[part 3 of 3: packages /AUTOSAR to /Volkswagen/EcuConfiguration]
AUTOSAR XML (schema 3.1.1)
package /AUTOSAR  (continued)
  module definition IoHwAbstraction [0..1]  # Configuration of IO HW Abstraction.
    container IoHwAbEcuSignalGroup [0..*]  # This container contains the configuration (parameters) of all ECU signals groups implemented in the IO Hardware Abstraction Module
      container IoHwAbDiscSigGrpInput [0..*]  # This container contains the description of a discrete ECU signal group. The container IoHwAb_Discrete_SignalGroup contains several IoHwAb_Class_Discrete_Input sub-containers
        reference IoHwAbDiscSigGrpInMember [1..*]: destination=IoHwAbDiscreteInput  # Each member of the signal group is referenced by an instance of tthis element. In the IO HW Abstraction SWS, individual signals are aggregated by the signal group instead of referenced, but by using references it is still possible to have the same signal being par of several signal groups, as intended in the SWS.
      container IoHwAbDiscSigGrpOutput [0..*]  # This container contains the description of a discrete ECU signal group. The container IoHwAb_Discrete_SignalGroup contains several IoHwAb_Class_Discrete_Output sub-containers.
        reference IoHwAbDiscSigGrpOutMember [1..*]: destination=IoHwAbDiscreteOutput  # Each member of the signal group is referenced by an instance of tthis element. In the IO HW Abstraction SWS, individual signals are aggregated by the signal group instead of referenced, but by using references it is still possible to have the same signal being par of several signal groups, as intended in the SWS.
    container IoHwAbEcuSignals [0..*]  # This container contains the configuration (parameters) of all ECU signals implemented in the IO Hardware Abstraction Module. Remarks: - The IO Hardware Abstraction module is an ECU firmware module. That means that the implementation shall fit only to the ECU hardware. The implementer has to develop only the functionality needed (eg: if there is no pulse width ECU signal configurated, the pulse width abstraction will not be available. - At least one ECU signal shall be configurated to have the module.
      container IoHwAbAnalogInput [0..*]  # This container contains the description of an analog ECU signal used as input. The operation available through the Port is a OP_GET.
        boolean IoHwAbAnaInputFilter  # This parameter specifies if the ECU analog signal is filtered
        boolean IoHwAbAnaInputReport  # This parameter specifies if the report features is activated
        integer IoHwAbAnaInputSamplingRate  # This parameter specifies the sampling rate for an analog input
        container IoHwAbAnalog  # This container contains common description of a all ECU signals from class analog.
          integer IoHwAbAnalogBswRange: 0..  # This parameter gives the BSW Range used for an analog signal, according to the datatype
          integer IoHwAbAnalogMaxAge  # This parameter gives the maximum age of an ECU analog signal
          string IoHwAbAnalogBswResolution  # This parameter gives the resolution used for an analog signal
          string IoHwAbAnalogDataType  # This parameter gives the DataType used for an analog signal
          string IoHwAbAnalogUnit  # This parameter gives the unit used for an analog signal
      container IoHwAbAnalogOutput [0..*]  # This container contains the description of an analog ECU signal used as output. The operation available through the Port is a OP_SET.
        boolean IoHwAbAnaOutputFailureMoni  # This parameter specifies if the ECU analog Output is monitored, to detect failure
        boolean IoHwAbAnaOutputPulseTest  # This parameter specifies if an test pulse is used to detect failure on the ECU analog Output
        container IoHwAbAnalog  # This container contains common description of a all ECU signals from class analog.
          integer IoHwAbAnalogBswRange: 0..  # This parameter gives the BSW Range used for an analog signal, according to the datatype
          integer IoHwAbAnalogMaxAge  # This parameter gives the maximum age of an ECU analog signal
          string IoHwAbAnalogBswResolution  # This parameter gives the resolution used for an analog signal
          string IoHwAbAnalogDataType  # This parameter gives the DataType used for an analog signal
          string IoHwAbAnalogUnit  # This parameter gives the unit used for an analog signal
      container IoHwAbDiscreteDiagnosis [0..*]  # This container contains the description of a discrete ECU signal used as diagnosis.
        container IoHwAbDiscrete  # This container contains common description of a all ECU signals from class discrete
          boolean IoHwAbDiscreteBswRange  # This parameter gives all possible values of an ECU discrete signal
          boolean IoHwAbDiscreteDatatype  # This parameter gives the DataType used for a discrete signal
          integer IoHwAbDiscreteMaxAge  # This parameter gives the maximum age of an ECU discrete signal
      container IoHwAbDiscreteInput [0..*]  # This container contains the description of a discrete ECU signal used as input. The operation available through the Port is an OP_GET.
        boolean IoHwAbDiscInputReport  # This parameter specifies if the report features is activated FALSE represents no report if a significant change occurs TRUE represents repot if a significant change occurs
        boolean IoHwAbDiscInputWakeup  # This parameter specifies if the ECU pin is a wakeup input TRUE represents a wakeup Input. During sleep mode, a change is reported to the module. In case of a valid reason, the ECU state manager will be restarted to validate the wakeup. FALSE represents a simple discrete Input.
        integer IoHwAbDiscInputDebounce  # This parameter specifies if the ECU discrete signal is filtered / debounced 0 represents Debouncing deactivated N represents Debouncing activated, N values sampled before value is available
        container IoHwAbDiscrete  # This container contains common description of a all ECU signals from class discrete
          boolean IoHwAbDiscreteBswRange  # This parameter gives all possible values of an ECU discrete signal
          boolean IoHwAbDiscreteDatatype  # This parameter gives the DataType used for a discrete signal
          integer IoHwAbDiscreteMaxAge  # This parameter gives the maximum age of an ECU discrete signal
      container IoHwAbDiscreteOutput [0..*]  # This container contains the description of a discrete ECU signal used as Output. The operation available through the Port is a OP_SET.
        boolean IoHwAbDiscOutputFailureMoni  # This parameter specifies if the ECU discrete Output is monitored, to detect failure TRUE represents that the ECU Signal is a monitored Output. Failures on this Output are detected and managed by the module FALSE represents that the ECU Signal is a simple discrete Output.
        boolean IoHwAbDiscOutputPulseTest  # This parameter specifies if an test pulse is used to detect failure on the ECU discrete Output TRUE represents that a Test Pulse is used for failure monitoring FALSE represents that no Test Pulse is used for failure monitoring
        container IoHwAbDiscrete  # This container contains common description of a all ECU signals from class discrete
          boolean IoHwAbDiscreteBswRange  # This parameter gives all possible values of an ECU discrete signal
          boolean IoHwAbDiscreteDatatype  # This parameter gives the DataType used for a discrete signal
          integer IoHwAbDiscreteMaxAge  # This parameter gives the maximum age of an ECU discrete signal
      container IoHwAbPwDutyCycleInput [0..*]  # This container contains specific description for an input ECU signal from class pulse width, handling especially the characteristic DutyCycle The operation available through the Port is a OP_GET
        boolean IoHwAbPwdcInputWakeup  # This parameter specifies if the ECU pin is a wakeup input
        container IoHwAbPwDutyCycle  # This container contains common description of a all ECU signals from class pulse width, handling especially the characteristic duty cycle
          integer IoHwAbPwdcBswRange: 0..100  # This parameter gives the BSW Range for a pulse width signal
          string IoHwAbPwdcUnit  # This parameter gives the unit for an ECU signal, handling especially the characteristic period
          container IoHwAbPulseWidth  # This container contains common description of a all ECU signals from class pulse width
            integer IoHwAbPwBswResolution  # This parameter gives the resolution used for a pulse width ECU signal
            integer IoHwAbPwMaxAge  # This parameter gives the maximum age for a pulse width ECU signal
            string IoHwAbPwDatatype  # This parameter gives the DataType used for a pulse width signal
      container IoHwAbPwDutyCycleOutput [0..*]  # This container contains specific description for an output ECU signal from class pulse width, handling especially the characteristic DutyCycle. The operation available through the Port is a OP_SET.
        boolean IoHwAbPwdcOutputFailureMoni  # This parameter specifies if the ECU Output is monitored, to detect failure
        boolean IoHwAbPwdcOutputPulseTest  # This parameter specifies if an test pulse is used to detect failure on the ECU Output
        container IoHwAbPwDutyCycle  # This container contains common description of a all ECU signals from class pulse width, handling especially the characteristic duty cycle
          integer IoHwAbPwdcBswRange: 0..100  # This parameter gives the BSW Range for a pulse width signal
          string IoHwAbPwdcUnit  # This parameter gives the unit for an ECU signal, handling especially the characteristic period
          container IoHwAbPulseWidth  # This container contains common description of a all ECU signals from class pulse width
            integer IoHwAbPwBswResolution  # This parameter gives the resolution used for a pulse width ECU signal
            integer IoHwAbPwMaxAge  # This parameter gives the maximum age for a pulse width ECU signal
            string IoHwAbPwDatatype  # This parameter gives the DataType used for a pulse width signal
      container IoHwAbPwPeriodInput [0..*]  # This container contains specific description for an input ECU signal from class pulse width, handling especially the characteristic period
        boolean IoHwAbPwpInputWakeup  # This parameter specifies if the ECU pin is a wakeup input
        container IoHwAbPwPeriod  # This container contains common description of a all ECU signals from class pulse width, handling especially the characteristic period
          integer IoHwAbPwpBswRange: -100..100  # This parameter gives the BSW Range for a pulse width signal (in percent)
          string IoHwAbPwpUnit  # This parameter gives the unit for an ECU signal, handling especially the characteristic period
          container IoHwAbPulseWidth  # This container contains common description of a all ECU signals from class pulse width
            integer IoHwAbPwBswResolution  # This parameter gives the resolution used for a pulse width ECU signal
            integer IoHwAbPwMaxAge  # This parameter gives the maximum age for a pulse width ECU signal
            string IoHwAbPwDatatype  # This parameter gives the DataType used for a pulse width signal
      container IoHwAbPwPeriodOutput [0..*]  # This container contains specific description for an output ECU signal from class pulse width, handling especially the characteristic period The operation available through the Port is a OP_SET.
        boolean IoHwAbPwpOutputFailureMoni  # This parameter specifies if the ECU Output is monitored, to detect failure
        boolean IoHwAbPwpOutputPulseTest  # This parameter specifies if an test pulse is used to detect failure on the ECU Output
        container IoHwAbPwPeriod  # This container contains common description of a all ECU signals from class pulse width, handling especially the characteristic period
          integer IoHwAbPwpBswRange: -100..100  # This parameter gives the BSW Range for a pulse width signal (in percent)
          string IoHwAbPwpUnit  # This parameter gives the unit for an ECU signal, handling especially the characteristic period
          container IoHwAbPulseWidth  # This container contains common description of a all ECU signals from class pulse width
            integer IoHwAbPwBswResolution  # This parameter gives the resolution used for a pulse width ECU signal
            integer IoHwAbPwMaxAge  # This parameter gives the maximum age for a pulse width ECU signal
            string IoHwAbPwDatatype  # This parameter gives the DataType used for a pulse width signal
    container IoHwAbGeneral  # This container contains common description for the IO Hardware Abstraction module
      boolean IoHwAbDevErrorDetect  # Switches the Development Error Detection and Notification ON or OFF
      boolean IoHwAbVersionInfoApi  # Pre-processor switch to enable / disable the API to read out the modules version information.
  module definition Lin [0..*]: variants pre-compile/post-build  # Configuration of the Lin (LIN driver) module.
    container LinGeneral
      boolean LinDevErrorDetect: set at pre-compile  # Switches the Development Error Detection and Notification ON or OFF.
      boolean LinVersionInfoApi: set at pre-compile  # Switches the Lin_GetVersionInfo function ON or OFF.
      integer LinIndex: set at pre-compile  # Specifies the InstanceId of this module instance. If only one instance is present it shall have the Id 0.
      integer LinTimeoutDuration: set at pre-compile  # Specifies the maximum number of loops for blocking function until a timeout is raised in short term wait loops
    container LinGlobalConfig: multiple-configuration-container=true  # This container contains the global configuration parameter of the Lin driver. This container is a MultipleConfigurationContainer, i.e. this container and its sub-containers exit once per configuration set.
      container LinChannel [1..*]  # This container contains the configuration (parameters) of the LIN Controller(s).
        boolean LinChannelWakeUpSupport: set at pre-compile  # Specifies if the LIN hardware channel supports wake up functionality
        integer LinChannelBaudRate: 1000..20000, set at pre-compile in variant pre-compile / post-build in variant post-build  # Specifies the baud rate of the LIN channel
        integer LinChannelId: set at pre-compile, symbolic-name-value=true  # Identifies the LIN channel. Replaces LIN_CHANNEL_INDEX_NAME from the LIN SWS.
        reference LinClockRef: set at pre-compile in variant pre-compile / post-build in variant post-build, destination=McuClockReferencePoint  # Reference to the LIN clock source configuration, which is set in the MCU driver configuration.
        symbolic name reference LinChannelEcuMWakeUpSource [0..1]: destination=EcuMWakeupSource  # This parameter contains a reference to the Wakeup Source for this controller as defined in the ECU State Manager. Implementation Type: reference to EcuM_WakeupSourceType
  module definition LinIf [0..1]: variants pre-compile/link-time/post-build  # Configuration of the LinIf (LIN Interface) module.
    container LinIfGeneral
      boolean LinIfDevErrorDetect: set at pre-compile  # Switches the Development Error Detection and Notification ON or OFF.
      boolean LinIfMultipleDriversSupported: set at pre-compile  # States if multiple drivers are included in the LIN Interface or not. The reason for this parameter is to reduce the size of LIN Interface if multiple drivers are not used.
      boolean LinIfNcOptionalRequestSupported: set at pre-compile  # States if the node configuration commands Assign NAD and Conditional Change NAD are supported.
      boolean LinIfTpSupported: set at pre-compile  # States if the TP is included in the LIN Interface or not. The reason for this parameter is to reduce the size of LIN Interface if the TP is not used.
      boolean LinIfVersionInfoApi: set at pre-compile  # Switches the LinIf_GetVersionInfo function ON or OFF.
    container LinIfGlobalConfig: multiple-configuration-container=true  # This container contains the global configuration parameter of the LinIf. It is a MultipleConfigurationContainer, i.e. this container and its sub-containers exit once per configuration set.
      float LinIfTimeBase: set at link in variant link-time / pre-compile in variant pre-compile / post-build in variant post-build  # The time-base for this channel in s (normally 0.002, 0.005 or 0.010s)
      container LinIfChannel [1..*]
        integer LinIfChannelId: set at link in variant link-time+post-build / pre-compile in variant pre-compile, symbolic-name-value=true  # Internal ID for the channel on LIN Interface level. This parameter shall map the NetworkHandleType to the physical LIN channel. Implementation Type: NetworkHandleType
        integer LinIfScheduleRequestQueueLength: 1..255, set at link in variant link-time / pre-compile in variant pre-compile / post-build in variant post-build  # Number of schedule requests the schedule table manager can handle for this channel.
        symbolic name reference LinIfChannelRef: destination=LinChannel  # Reference to the used channel in Lin. Replaces LINIF_CHANNEL_INDEX
        container LinIfFrame [0..*]  # Generic container for all types of LIN frames.
          enumeration LinIfChecksumType: {CLASSIC, ENHANCED}, set at link in variant link-time / pre-compile in variant pre-compile / post-build in variant post-build  # Type of checksum that the frame is using.
          enumeration LinIfFrameType: {ASSIGN, ASSIGN_NAD, CONDITIONAL, EVENT_TRIGGERED, FREE, MRF, SPORADIC, SRF, UNASSIGN, UNCONDITIONAL}, set at link in variant link-time / pre-compile in variant pre-compile / post-build in variant post-build  # Type of frame that is described (e.g. sporadic frame). Note that types 7-11 are the fixed MRF types. The sporadic slot is not found among the frame types. A sporadic slot is a set of sporadic frames.
          integer LinIfFramePriority: 0..255, set at link in variant link-time / pre-compile in variant pre-compile / post-build in variant post-build  # Priority of an unconditional frame if used as a sporadic frame or in case of collision resolving of event triggered frames
          integer LinIfLength: 1..8, set at link in variant link-time / pre-compile in variant pre-compile / post-build in variant post-build  # Length of the LIN SDU in bytes.
          integer LinIfPid: 0.., set at link in variant link-time / pre-compile in variant pre-compile / post-build in variant post-build  # Protected ID of the LIN frame. There is no reason to calculate the Parity in run-time.
          integer LinIfTxTargetPduId: set at link in variant link-time / pre-compile in variant pre-compile / post-build in variant post-build  # Identifier of the frame for the upper layer
          string LinIfFrameName [0..1]: set at link in variant link-time / pre-compile in variant pre-compile / post-build in variant post-build  # Optional frame name used to cross-reference with a LDF
          choice container LinIfPduDirection  # Direction of the frame
            container LinIfInternalPdu [0..1]  # Represents a Diagnostic or Configuration frame : no Message ID (no PduId).
            container LinIfRxPdu [0..1]  # represents a received PDU/frame
              integer LinIfRxPduId: set at link in variant link-time / pre-compile in variant pre-compile / post-build in variant post-build, symbolic-name-value=true  # dentifier of the frame for the LIN Interface
              reference LinIfRxPduRef: destination=Pdu  # Reference to the PDU that is received in this frame.
            container LinIfSlaveToSlavePdu [0..1]  # represents a slave-to-slave PDU/frame. Master does only send the header but doesn't receive the response. Added for completeness
            container LinIfTxPdu [0..1]  # represents a transmitted PDU/frame
              integer LinIfTxPduId: set at link in variant link-time / pre-compile in variant pre-compile / post-build in variant post-build, symbolic-name-value=true  # Identifier of the frame for the upper layer. This id is only relevant for sporadic frames.
              reference LinIfTxPduRef: destination=Pdu  # Reference to the PDU that is transmitted in this frame.
          container LinIfFixedFrameSdu [0..1]  # In case this is a fixed frame this is the SDU (response). This value should represent an eight byte array. The Byte order shall be MSB first.
            integer LinIfFixedFrameSduBytePos: 1..8, set at link in variant link-time / pre-compile in variant pre-compile / post-build in variant post-build  # Index of the Byte in the SDU (response) 8 byte array.
            integer LinIfFixedFrameSduByteVal: 0..255, set at link in variant link-time / pre-compile in variant pre-compile / post-build in variant post-build  # Byte value in the SDU (response) 8-byte array.
          container LinIfSubstitutionFrames [0..*]  # List of unconditional Frames that can be sent in an event-triggered Frame or a sporadic Frame slot.
            reference LinIfSubstitutionFrameRef: destination=LinIfFrame  # Reference to an unconditional Frame that can be sent in an event-triggered Frame or a sporadic Frame slot.
        container LinIfMaster  # Each Master can only be connected to one physical channel. This could be compared to the Node parameter in a LDF file.
          integer LinIfJitter: set at pre-compile  # Specifies the difference and the maximum and the minimum delay (ms)
        container LinIfScheduleTable [1..*]  # Describes a schedule table. Each LinIfChannel may have several schedule tables. Each schedule table can only be connected to one channel.
          enumeration LinIfResumePosition: {CONTINUE_AT_IT_POINT, START_FROM_BEGINNING}, set at link in variant link-time / pre-compile in variant pre-compile / post-build in variant post-build  # Defines, where a schedule table shall be proceeded in case if it has been interrupted by a run-once table or MRF/SRF.
          enumeration LinIfRunMode: {RUN_CONTINUOUS, RUN_ONCE}, set at link in variant link-time / pre-compile in variant pre-compile / post-build in variant post-build  # The schedule table can be executed in two different modes.
          integer LinIfSchedulePriority: 0..255, set at link in variant link-time / pre-compile in variant pre-compile / post-build in variant post-build  # Priority of the schedule table. The priority is used in the schedule table manager. The RUN_ONCE run mode schedules shall not have equal priority. 0 Reserved for NULL__SCHEDULE 1..254 Only for RUN_ONCE 255 Only RUN_CONTINUOUS
          integer LinIfScheduleTableIndex: set at link in variant link-time / pre-compile in variant pre-compile / post-build in variant post-build, symbolic-name-value=true  # This is the unique index used by upper layers to identify a schedule. Note that the NULL_SCHEDULE for each channel has index 0.
          string LinIfScheduleTableName [0..1]: set at link in variant link-time / pre-compile in variant pre-compile / post-build in variant post-build  # Optional schedule name used to cross-reference with a LDF. This parameter shall always be accompanied by LIN_IF_SCHEDULE_INDEX.
          container LinIfEntry [0..*]  # Describes an entry in the schedule table (also known as Frame Slot).
            float LinIfDelay: set at link in variant link-time / pre-compile in variant pre-compile / post-build in variant post-build  # Delay to next frame in schedule table in [s]
            integer LinIfEntryIndex  # Position of the Frame Entry in the Schedule Table.
            reference LinIfCollisionResolvingRef [0..1]: destination=LinIfScheduleTable  # Reference to the schedule table, which resolves the collision.
            reference LinIfFrameRef [1..*]: set at link in variant link-time / pre-compile in variant pre-compile / post-build in variant post-build, destination=LinIfFrame  # Reference to the frames that belong to this schedule table entry.
        container LinIfSlave [0..*]  # The Node attributes of the Slaves are provided with these parameter.
          integer LinIfConfiguredNad: set at pre-compile  # Definition of the initial node address
          integer LinIfFunctionId: set at pre-compile  # LIN function ID
          integer LinIfResponseErrorBitPos: set at pre-compile  # Specifies the frame and the position in the frame
          integer LinIfSupplierId: set at pre-compile  # LIN Supplier ID
          integer LinIfVariant: set at pre-compile  # Specifies the Variant ID
          string LinIfProtocolVersion: set at pre-compile  # Defines the LIN Protocol version which is used by the slave.
          reference LinIfResponseErrorEventRef: destination=DemEventParameter  # Reference to DEM Event
          reference LinIfResponseErrorFrameRef: destination=LinIfFrame  # Reference to the frame which contains the response error bit.
          container LinIfNodeComposition  # Generic container that describes the node composition
            string LinIfNodeName: set at pre-compile
        container LinIfWakeUpSource [0..1]  # This container contains the configuration (parameters) needed to configure a wakeup capable channel
          symbolic name reference LinIfChannelWakeupInfo: destination=EcuMWakeupSource  # If the wakeup-capability is true the wakeup source referenced is transmitted to the ECU State Manager (EcuM) . Implementation Type: reference to EcuM_WakeupSourceType
  module definition LinSM [0..1]: variants pre-compile/link-time  # Configuration of the Lin State Manager module.
    container LinSMChannel [1..*]: multiple-configuration-container=true  # Describes each LIN channel the LinSM is connected to.
      boolean LinSMSleepSupport: set at link in variant link-time / pre-compile in variant pre-compile  # Some LIN clusters does not need sleep, they will just shut off. This parameter will affect the behavior to achieve the no communication state. True - The LinSM will request the LinIf to send the goto sleep command before going to no communication state LINSM_NOCOM. False - The LinSM will directly go to no communication state LINSM_NOCOM.
      float LinSMConfirmationTimeout: set at link in variant link-time / pre-compile in variant pre-compile  # Timeout in seconds for the goto sleep and wakeup calls to LinIf. The timeout must be longer than a goto-sleep command on the bus (i.e. it is bit rate dependent).
      symbolic name reference LinSMChannelIndex: destination=LinIfChannel  # Index of the controller. To be able to interface to the correct hw.
      container LinSMSchedule [1..*]  # The schedule references to a schedule that is located in the LinIf configuration. Moreover, the PDU groups are located in the COM configuration. Note that there are two references to PDU groups. The simple reason is that a PDU group is only allowed to contain one direction (TX or RX).
        symbolic name reference LinSMRxPduGroupRef: destination=ComIPduGroup  # This is a reference to the PDU group containing the received frames in the Com configuration
        symbolic name reference LinSMScheduleIndexRef: destination=LinIfScheduleTable  # Reference to a schedule table in the LinIf configuration
        symbolic name reference LinSMTxPduGroupRef: destination=ComIPduGroup  # This is a reference to the PDU group containing the transmitted frames in the Com configuration
    container LinSMGeneral  # The general parameters fo this module.
      boolean LinSMDevErrorDetect: set at pre-compile  # Switches the Development Error Detection and Notification ON or OFF.
      boolean LinSMVersionInfoApi: set at pre-compile  # Switches the LinSM_GetVersionInfo function ON or OFF.
  module definition LinTp [0..1]: variants pre-compile/link-time/post-build  # Singleton descriptor for the LIN Transport Protocol.
    container LinTpGeneral  # Container that holds all LIN transport protocol general parameters.
      boolean LinTpVersionInfoApi: set at pre-compile  # Switches the LinTp_GetVersionInfo function ON or OFF.
    container LinTpGlobalConfig: multiple-configuration-container=true  # This container contains the global configuration parameter of the LinTp. It is a MultipleConfigurationContainer, i.e. this container and its sub-containers exit once per configuration set.
      integer LinTpNumberOfRxNSdu: set at link in variant link-time / pre-compile in variant pre-compile / post-build in variant post-build  # Number of transport protocol messages that can be received for all channels this node is connected to. Can't that be calculated from the NSdus?
      integer LinTpNumberOfTxNSdu: set at link in variant link-time / pre-compile in variant pre-compile / post-build in variant post-build  # Number of transport protocol messages that can be transmitted for all channels this node is connected to.
      container LinTpRxNSdu [0..*]  # For each received N-SDU on any channel the node is connected to.
        integer LinTpDl: set at link in variant link-time / pre-compile in variant pre-compile / post-build in variant post-build  # Data Length Code of this RxNsdu. In case of variable length message, this value indicates the minimum data length. Range of minimum length is 1 to 4095. Note that this is not relevant for Tx. The reason for this is to have identical structures for Tx and Rx.
        integer LinTpRxNSduId: set at link in variant link-time / pre-compile in variant pre-compile / post-build in variant post-build, symbolic-name-value=true  # The identifier of the Transport Protocol message. This ID will be the one that is communicated with upper layers.
        integer LinTpRxNSduNad: set at link in variant link-time / pre-compile in variant pre-compile / post-build in variant post-build  # A N-SDU transported on LIN is identified using the NAD for the specific slave.
        reference LinTpRxNSduPduRef: destination=Pdu  # Reference to the global PDU
        symbolic name reference LinTpRxNSduChannelRef: destination=LinIfChannel  # Index of the channel this N-SDU belongs to.
      container LinTpTxNSdu [0..*]  # For each transmitted N-SDU on any channel the node is connected to.
        integer LinTpTxNSduId: set at link in variant link-time / pre-compile in variant pre-compile / post-build in variant post-build, symbolic-name-value=true  # The identifier of the Transport Protocol message. This ID will be the one that is communicated with upper layers.
        integer LinTpTxNSduNad: set at link in variant link-time / pre-compile in variant pre-compile / post-build in variant post-build  # A N-SDU transported on LIN is identified using the NAD for the specific slave.
        reference LinTpTxNSduPduRef: destination=Pdu  # Reference to the global PDU
        symbolic name reference LinTpTxNSduChannelRef: destination=LinIfChannel  # Index of the channel this N-SDU belongs to.
  module definition Mcu [0..1]: variants pre-compile/post-build  # Configuration of the Mcu (Microcontroler Unit) module.
    container McuGeneralConfiguration  # This container contains the configuration (parameters) of the MCU driver.
      boolean McuDevErrorDetect: set at pre-compile  # Pre-processor switch for enabling the development error detection and reporting.
      boolean McuPerformResetApi: set at pre-compile  # Pre-processor switch to enable / disable the use of the function Mcu_PerformReset()
      boolean McuVersionInfoApi: set at pre-compile  # Pre-processor switch to enable / disable the API to read out the modules version information.
    container McuModuleConfiguration: multiple-configuration-container=true  # This container contains the configuration (parameters) of the MCU driver
      derived integer McuNumberOfMcuModes: calculation-formula=number of configured mcumodesettingconf, calculation-language=INFORMAL  # This parameter shall represent the number of Modes available for the MCU. calculationFormula = Number of configured McuModeSettingConf
      derived integer McuRamSectors: set at pre-compile in variant pre-compile / post-build in variant post-build, calculation-formula=number of configured mcuramsectorsettingconf, calculation-language=INFORMAL  # This parameter shall represent the number of RAM sectors available for the MCU. calculationFormula = Number of configured McuRamSectorSettingConf
      enumeration McuClockSrcFailureNotification: {DISABLED, ENABLED}, set at pre-compile in variant pre-compile / post-build in variant post-build  # Enables/Disables clock failure notification. In case this feature is not supported by HW the setting should be disabled.
      integer McuResetSetting [0..1]: set at pre-compile  # This parameter relates to the MCU specific reset configuration. This applies to the function Mcu_PerformReset, which performs a microcontroller reset using the hardware feature of the microcontroller.
      container McuClockSettingConfig  # This container contains the configuration (parameters) for the Clock settings of the MCU. Please see MCU031 for more information on the MCU clock settings.
        container McuClockReferencePoint [1..*]  # This container defines a reference point in the Mcu Clock tree. It defines the frequency which then can be used by other modules as an input value. Lower multiplictiy is 1, as even in the simpliest case (only one frequency is used), there is one frequency to be defined.
          float McuClockReferencePointFrequency: set at pre-compile in variant pre-compile / post-build in variant post-build  # This is the frequency for the specific instance of the McuClockReferencePoint container. It shall be givn in Hz.
      container McuModeSettingConf [1..*]  # This container contains the configuration (parameters) for the Mode setting of the MCU. Please see MCU035 for more information on the MCU mode settings.
        integer McuMode: set at pre-compile in variant pre-compile / post-build in variant post-build, symbolic-name-value=true  # The parameter represents the MCU Mode settings.
      container McuRamSectorSettingConf [0..*]  # This container contains the configuration (parameters) for the RAM Sector setting. Please see MCU030 for more information on RAM sec-tor settings.
        integer McuRamDefaultValue: set at pre-compile in variant pre-compile / post-build in variant post-build  # This parameter shall represent the Data pre-setting to be initialized
        integer McuRamSectionBaseAddress: set at pre-compile in variant pre-compile / post-build in variant post-build  # This parameter shall represent the MCU RAM section base address
        integer McuRamSectionSize: set at pre-compile in variant pre-compile / post-build in variant post-build  # This parameter shall represent the MCU RAM Section size
  module definition MemIf [0..1]: variants pre-compile  # Configuration of the MemIf (Memory Abstraction Interface) module.
    container MemIfGeneral  # Configuration of the memory abstraction interface (Memif) module.
      boolean MemIfDevErrorDetect: set at pre-compile  # Pre-processor switch to enable and disable development error detection. true: Development error detection enabled. false: Development error detection disabled.
      boolean MemIfVersionInfoApi: set at pre-compile  # Pre-processor switch to enable / disable the API to read out the modules version information. true: Version info API enabled. false: Version info API disabled.
      derived integer MemIfNumberOfDevices: 1..255, set at pre-compile, calculation-language=INFORMAL  # Concrete number of underlying memory abstraction modules.
  module definition Nm [0..1]: variants pre-compile  # The Generic Network Management Interface module
    container NmGlobalConfig  # This container contains all global configuration parameters of the Nm Interface.
      boolean NmBusSynchronizationEnabled: set at pre-compile  # Pre-processor switch for enabling bus synchronization support. This feature is required for gateway nodes only.
      boolean NmComControlEnabled: set at pre-compile  # Pre-processor switch for enabling the Communication Control support.
      boolean NmCoordinatorSupportEnabled: set at pre-compile, default-value=false  # Switch to inform if NM coordinator needs to be supported.
      boolean NmDevErrorDetect: set at pre-compile, default-value=false  # Pre-processor switch for enabling development error detection and notification.
      boolean NmMultipleChannelsEnabled: set at pre-compile, default-value=false  # Pre-processor switch for enabling channel multiplicity support.
      boolean NmNodeDetectionEnabled: set at pre-compile  # Pre-processor switch for enabling the Request Repeat Message Request support.
      boolean NmNodeIdEnabled: set at pre-compile  # Pre-processor switch for enabling the source node identifier.
      boolean NmOsekSupportEnabled: set at pre-compile, default-value=false  # Switch to inform if NM coordinator needs to support direct OSEK NM.
      boolean NmPassiveModeEnabled: set at pre-compile  # Pre-processor switch for enabling support of the Passive Mode.
      boolean NmPduRxIndicationEnabled: set at pre-compile  # Pre-processor switch for enabling the PDU Rx Indication.
      boolean NmRemoteSleepIndEnabled: set at pre-compile  # Pre-processor switch for enabling remote sleep indication support. This feature is required for gateway nodes only.
      boolean NmStateChangeIndEnabled: set at pre-compile  # Pre-processor switch for enabling the CAN Network Management state change notification.
      boolean NmUserDataEnabled: set at pre-compile  # Pre-processor switch for enabling user data support.
      boolean NmVersionInfoApi: set at pre-compile  # Pre-processor switch for enabling version info API support.
      float NmCycletimeMainFunction: set at pre-compile  # The period between successive calls to the Main Function of the NM Interface in seconds.
      integer NmAutosarGatewayRounds: set at pre-compile  # Number of rounds the coordinator shall keep a bus which runs AUTOSAR NM awake after all nodes including itself are ready to sleep.
      integer NmNumberOfChannels: 1..255, set at pre-compile  # Number of NM channels allowed within one ECU.
      integer NmOsekGatewayRounds: set at pre-compile  # Number of rounds the coordinator shall keep a bus which runs OSEK NM awake after all nodes including itself are ready to sleep.
      container NmChannelConfig [1..*]  # This container contains the configuration (parameters) of the bus channel(s). The channel parameter shall be harmonized within the whole communication stack.
        enumeration NmBusType: {NM_BUS_TYPE_CAN, NM_BUS_TYPE_FR, NM_BUS_TYPE_LIN}, set at pre-compile  # Identifies the bus type of the channel. LIN is not yet supported.
        integer NmChannelId: 0..255, set at pre-compile, symbolic-name-value=true  # Channel identification number of the corresponding channel.
        symbolic name reference NmComMChannelRef: destination=ComMChannel  # Reference to the corresponding ComM Channel.
  module definition NvM [0..1]: variants pre-compile  # Configuration of the NvM (NvRam Manager) module.
    container NvmBlockDescriptor [1..65536]  # Container for a management structure to configure the composition of a given NVRAM Block Management Type. Its multiplicity describes thenumber of configured NVRAM blocks, one block is required to be configured. The NVRAM block descriptors are condensed in the NVRAM block descriptor table.
      boolean NvmBlockUseCrc: set at pre-compile  # Defines CRC usage for the NVRAM block, i.e. memory space for CRC is reserved in RAM and NV memory. true: CRC will be used for this NVRAM block. false: CRC will not be used for this NVRAM block.
      boolean NvmBlockWriteProt: set at pre-compile  # Defines an initial write protection of the NV block true: Initial block write protection is enabled. false: Initial block write protection is disabled.
      boolean NvmCalcRamBlockCrc: set at pre-compile  # Defines CRC (re)calculation for the permanent RAM block true: CRC will be (re)calculated for this permanent RAM block. false: CRC will not be (re)calculated for this permanent RAM block.
      boolean NvmResistantToChangedSw: set at pre-compile  # Defines whether a NVRAM block shall be treated resistant to configuration changes or not. If there is no default data available at configuration time then the application shall be responsible for providing the default initialization data. In this case the application has to use NvM_GetErrorStatus()to be able to distinguish between first initialization and corrupted data. true: NVRAM block is resistant to changed software. false: NVRAM block is not resistant to changed software.
      boolean NvmSelectBlockForReadall: set at pre-compile  # NVM117: Defines whether a NVRAM block shall be processed during NvM_ReadAll or not. This configuration parameter has only influence on those NVRAM blocks which are configured to have a permanent RAM block. NVM245: Blocks of management type NVM_BLOCK_DATASET shall not be loaded automatically upon start-up. Thus the selection of blocks, which belong to block management type NVM_BLOCK_DATASET, shall not be possible for the service NvM_ReadAll. true: NVRAM block shall be processed by NvM_ReadAll false: NVRAM block shall not be processed by NvM_ReadAll
      boolean NvmWriteBlockOnce: set at pre-compile  # Defines write protection after first write. The NVRAM manager sets the write protection bit after the NV block was written the first time. This means that some of the NV blocks in the NVRAM should never be erased nor be replaced with the default ROM data after first initialization. [NVM276]. true: Defines write protection after first write is enabled. false: Defines write protection after first write is disabled.
      derived integer NvmNvBlockBaseNumber: set at pre-compile, calculation-language=INFORMAL  # Configuration parameter to perform the link between the NVM_NVRAM_BLOCK_IDENTIFIER used by the SW-Cs and the FEE_BLOCK_NUMBER expected by the memory abstraction modules. The parameter relates directly to the FEE_BLOCK_NUMBER or EA_BLOCK_NUMBER with all configured NVM_DATASET_SELECTION_BITS set to zero (ref. to chapter 7.1.2.1). Calculation Formula: "value = TargetBlockReference.[Ea/Fee]BlockConfiguration.[Ea/Fee]BlockNumber"
      derived integer NvmNvramDeviceId: set at pre-compile, calculation-language=INFORMAL  # Defines the NVRAM device ID where the NVRAM block is located. Calculation Formula: "value = TargetBlockReference.[Ea/Fee]BlockConfiguration.[Ea/Fee]DeviceIndex"
      enumeration NvmBlockCRCType: {NVM_CRC16, NVM_CRC32}, set at pre-compile  # Defines CRC data width for the NVRAM block. Default: NVM_CRC16, i.e. CRC16 will be used if NVM_BLOCK_USE_CRC==TRUE
      enumeration NvmBlockManagementType: {NVM_BLOCK_DATASET, NVM_BLOCK_NATIVE, NVM_BLOCK_REDUNDANT}, set at pre-compile  # Defines the block management type for the NVRAM block.[NVM137]
      function name NvmInitBlockCallback: set at pre-compile  # Entry address of a block specific callback routine which shall be called if no ROM data is available for initialization of the NVRAM block. If a NULL pointer is configured, no specific callback routine shall be called for initialization of the NVRAM block with default data.
      function name NvmSingleBlockCallback: set at pre-compile  # Entry address of the block specific callback routine which shall be invoked on termination of each asynchronous single block request [NVM113].
      integer NvmBlockJobPriority: 0..255, set at pre-compile  # Defines the job priority for a NVRAM block (0 = Immediate priority).
      integer NvmNvBlockLength: 1..65535, set at pre-compile  # Defines the NV block data length in bytes
      integer NvmNvBlockNum: 1..255, set at pre-compile  # Defines the number of multiple NV blocks in a contiguous area according to the given block management type. 1-255 For NVRAM blocks to be configured of block management type NVM_BLOCK_DATASET. The actual range is limited according to NVM148. 1 For NVRAM blocks to be configured of block management type NVM_BLOCK_NATIVE 2 For NVRAM blocks to be configured of block management type NVM_BLOCK_REDUNDANT
      integer NvmNvramBlockIdentifier: 0.., set at pre-compile, symbolic-name-value=true  # Identification of a NVRAM block via a unique block identifier. Implementation Type: NvM_BlockIdType. min = 0 max = 2^(16- NVM_DATASET_SELECTION_BITS)-1 Reserved NVRAM block IDs: 0 -> to derive multi block request results via NvM_GetErrorStatus 1 -> redundant NVRAM block which holds the configuration ID
      integer NvmRomBlockNum: set at pre-compile  # Defines the number of multiple ROM blocks in a contiguous area according to the given block management type. 0-255 For NVRAM blocks to be configured of block management type NVM_BLOCK_DATASET. The actual range is limited according to NVM148. 0-1 For NVRAM blocks to be configured of block management type NVM_BLOCK_NATIVE 0-1 For NVRAM blocks to be configured of block management type NVM_BLOCK_REDUNDANT
      string NvmRamBlockDataAddress: set at pre-compile  # Defines the start address of the RAM block data. If a NULL pointer is configured, no permanent RAM data block is available for the selected block management type.
      string NvmRomBlockDataAddress: set at pre-compile  # Defines the start address of the ROM block data. If a NULL pointer is configured, no ROM block is available for the selected block management type.
      choice container NvmTargetBlockReference
        container NvmEaRef [0..1]  # EEPROM Abstraction
          symbolic name reference NvmNameOfEaBlock: destination=EaBlockConfiguration  # reference to EaBlock
        container NvmFeeRef [0..1]  # Flash EEPROM Emulation
          symbolic name reference NvmNameOfFeeBlock: destination=FeeBlockConfiguration  # reference to FeeBlock
    container NvmCommon  # Container for common configuration options.
      boolean NvmDevErrorDetect: set at pre-compile  # Pre-processor switch to enable and disable development error detection. true: Development error detection enabled. false: Development error detection disabled.
      boolean NvmDrvModeSwitch: set at pre-compile  # Preprocessor switch to enable switching memory drivers to fast mode during performing NvM_ReadAll and NvM_WriteAll true: Fast mode enabled. false: Fast mode disabled.
      boolean NvmDynamicConfiguration: set at pre-compile  # Preprocessor switch to enable the dynamic configuration management handling by the NvM_ReadAll request. true: Dynamic configuration management handling enabled. false: Dynamic configuration management handling disabled.
      boolean NvmJobPrioritization: set at pre-compile  # Preprocessor switch to enable job prioritization handling true: Job prioritization handling enabled. false: Job prioritization handling disabled.
      boolean NvmPollingMode: set at pre-compile  # Preprocessor switch to enable/disable the polling mode in the NVRAM Manager and at the same time disable/enable the callback functions useable by lower layers true: Polling mode enabled, callback function usage disabled. false: Polling mode disabled, callback function usage enabled.
      boolean NvmSetRamBlockStatusApi: set at pre-compile  # Preprocessor switch to enable the API NvM_SetRamBlockStatus. true: API NvM_SetRamBlockStatus enabled. false: API NvM_SetRamBlockStatus disabled.
      boolean NvmVersionInfoApi: set at pre-compile  # Pre-processor switch to enable / disable the API to read out the modules version information [NVM285], [NVM286]. true: Version info API enabled. false: Version info API disabled.
      enumeration NvmApiConfigClass: {NVM_API_CONFIG_CLASS_1, NVM_API_CONFIG_CLASS_2, NVM_API_CONFIG_CLASS_3}, set at pre-compile  # Preprocessor switch to enable some API calls which are related to NVM API configuration classes.
      function name NvmMultiBlockCallback: set at pre-compile  # Entry address of the common callback routine which shall be invoked on termination of each asynchronous multi block request
      integer NvmCompiledConfigId: 0..65535, set at pre-compile  # Configuration ID regarding the NV memory layout. This configuration ID shall be published as e.g. a SW-C shall have the possibility to write it to NV memory.
      integer NvmCrcNumOfBytes: 1..65535, set at pre-compile  # If CRC is configured for at least one NVRAM block, this parameter defines the maximum number of bytes which shall be processed within one cycle of job processing.
      integer NvmDatasetSelectionBits: 0..8, set at pre-compile  # Defines the number of least significant bits which shall be used to address a certain dataset of a NVRAM block within the interface to the memory hardware abstraction. 0..8: Number of bits which are used for dataset or redundant block addressing. 0: No dataset or redundant NVRAM blocks are configured at all, no selection bits required. 1: In case of redundant NVRAM blocks are configured, but no dataset NVRAM blocks.
      integer NvmMaxNoOfWriteRetries: 0..7, set at pre-compile  # Defines the maximum number of write retries for a NVRAM block with [NVM061]. Regardless of configuration a consistency check (and maybe write retries) are always forced for each block which is processed by the request NvM_WriteAll and NvM_WriteBlock.
      integer NvmSizeImmediateJobQueue: 1..255, set at pre-compile  # Defines the number of queue entries for the immediate priority job queue. If NVM_JOB_PRIORITIZATION is switched OFF this parameter shall be out of scope.
      integer NvmSizeStandardJobQueue: 1..255, set at pre-compile  # Defines the number of queue entries for the standard job queue.
  module definition Os [0..1]: variants pre-compile  # Configuration of the Os (Operating System) module.
    container OsAlarm [0..*]  # An OsAlarm may be used to asynchronously inform or activate a specific task. It is possible to start alarms automatically at system start-up depending on the application mode.
      reference OsAlarmAccessingApplication [0..*]: set at pre-compile, destination=OsApplication  # Reference to applications which have an access to this object.
      reference OsAlarmCounterRef: set at pre-compile, destination=OsCounter  # Reference to the assigned counter for that alarm
      choice container OsAlarmAction  # This container defines which type of notification is used when the alarm expires.
        container OsAlarmActivateTask [0..1]  # This container specifies the parameters to activate a task.
          reference OsAlarmActivateTaskRef: set at pre-compile, destination=OsTask  # Reference to the task that will be activated by that alarm action
        container OsAlarmCallback [0..1]  # This container specifies the parameters to call a callback OS alarm action.
          function name OsAlarmCallbackName: set at pre-compile  # Name of the function that is called when this alarm callback is triggered.
        container OsAlarmIncrementCounter [0..1]  # This container specifies the parameters to increment a counter.
          reference OsAlarmIncrementCounterRef: set at pre-compile, destination=OsCounter  # Reference to the counter that will be incremented by that alarm action
        container OsAlarmSetEvent [0..1]  # This container specifies the parameters to set an event
          reference OsAlarmSetEventRef: set at pre-compile, destination=OsEvent  # Reference to the event that will be set by that alarm action
          reference OsAlarmSetEventTaskRef: set at pre-compile, destination=OsTask  # Reference to the task that will be activated by that event
      container OsAlarmAutostart [0..1]  # If present this container defines if an alarm is started automatically at system start-up depending on the application mode.
        enumeration OsAlarmAutostartType: {ABSOLUTE, RELATIVE}, set at pre-compile  # This specifies the type of autostart for the alarm..
        integer OsAlarmAlarmTime: set at pre-compile  # The relative or absolute tick value when the alarm expires for the first time. Note that for an alarm which is RELATIVE the value must be at bigger than 0.
        integer OsAlarmCycleTime: set at pre-compile  # Cycle time of a cyclic alarm in ticks. If the value is 0 than the alarm is not cyclic.
        reference OsAlarmAppModeRef [1..*]: set at pre-compile, destination=OsAppMode  # Reference to the application modes for which the AUTOSTART shall be performed
    container OsAppMode [1..*]  # OsAppMode is the object used to define OSEK OS properties for an OSEK OS application mode. No standard attributes are defined for AppMode. In a CPU, at least one AppMode object has to be defined. [source: OSEK OIL Spec. 2.5] An OsAppMode called OSDEFAULTAPPMODE must always be there for OSEK compatilbility.
      integer OsAppModeId: set at pre-compile, symbolic-name-value=true  # Internal ID of an AppMode. Necessary, so that an AppMode is addressable by other modules.
    container OsApplication [0..*]  # An AUTOSAR OS must be capable of supporting a collection of OS objects (tasks, interrupts, alarms, hooks etc.) that form a cohesive functional unit. This collection of objects is termed an OS-Application. All objects which belong to the same OS-Application have access to each other. Access means to allow to use these objects within API services. Access by other applications can be granted separately.
      boolean OsTrusted: set at pre-compile, default-value=false  # Parameter to specify if an OS-Application is trusted or not. true: OS-Application is trusted false: OS-Application is not trusted (default)
      reference OsAppAlarmRef [0..*]: set at pre-compile, destination=OsAlarm  # Specifies the OsAlarms that belong to the OsApplication.
      reference OsAppCounterRef [0..*]: set at pre-compile, destination=OsCounter  # References the OsCounters that belong to the OsApplication.
      reference OsAppIsrRef [0..*]: set at pre-compile, destination=OsIsr  # references which OsIsrs belong to the OsApplication
      reference OsAppResourceRef [0..*]: set at pre-compile, destination=OsResource  # References the OsResources that belong to the OsApplication.
      reference OsAppScheduleTableRef [0..*]: set at pre-compile, destination=OsScheduleTable  # References the OsScheduleTables that belong to the OsApplication.
      reference OsAppTaskRef [0..*]: set at pre-compile, destination=OsTask  # references which OsTasks belong to the OsApplication
      reference OsRestartTask [0..1]: set at pre-compile, destination=OsTask  # Optionally one task of an OS-Application may be defined as Restart Task. Multiplicity = 1: Restart Task is activated by the Operating System if the protection hook requests it. Multiplicity = 0: No task is automatically started after a protection error happened.
      container OsApplicationHooks  # Container to structure the OS-Application-specific hooks
        boolean OsAppErrorHook: set at pre-compile  # Select the OS-Application error hook. true: Hook is called false: Hook is not called
        boolean OsAppShutdownHook: set at pre-compile  # Select the OS-Application specific shutdown hook for the OS-Application. true: Hook is called false: Hook is not called
        boolean OsAppStartupHook: set at pre-compile  # Select the OS-Application specific startup hook for the OS-Application. true: Hook is called false: Hook is not called
      container OsApplicationTrustedFunction [0..*]  # Container to structure the configration parameters of trusted functions
        function name OsTrustedFunctionName: set at pre-compile  # Trusted function (as part of a trusted OS-Application) available to other OS-Applications. This also supersedes the OSEK OIL attribute TRUSTED in APPLICATION because the optionality of this parameter is describing that already.
    container OsCounter [0..*]  # Configuration information for the counters that belong to the OsApplication.
      enumeration OsCounterType: {HARDWARE, SOFTWARE}, set at pre-compile  # This parameter contains the natural type or unit of the counter.
      float OsSecondsPerTick [0..1]: set at pre-compile  # Time of one hardware tick in seconds.
      integer OsCounterMaxAllowedValue: set at pre-compile  # Maximum possible allowed value of the system counter in ticks.
      integer OsCounterMinCycle: set at pre-compile  # The MINCYCLE attribute specifies the minimum allowed number of counter ticks for a cyclic alarm linked to the counter.
      integer OsCounterTicksPerBase: set at pre-compile  # The TICKSPERBASE attribute specifies the number of ticks required to reach a counterspecific unit. The interpretation is implementation-specific.
      reference OsCounterAccessingApplication [0..*]: set at pre-compile, destination=OsApplication  # Reference to applications which have an access to this object.
      container OsDriver [0..1]  # This Container contains the information who will drive the counter. This configuration is only valid if the counter has OsCounterType set to HARDWARE. If the container does not exist (multiplicity=0) the timer is managed by the OS internally (OSINTERNAL). If the container exists the OS can use the GPT interface to manage the timer. The user have to supply the GPT channel. If the counter is driven by some other (external to the OS) source (like a TPU for example) this must be described as a vendor specific extension.
        reference OsGptChannelRef [0..1]: set at pre-compile, destination=GptChannelConfiguration  # Reference to the GPT channel.
      container OsTimeConstant [0..*]  # Allows the user to define constants which can be e.g. used to compare time values with timer tick values. A time value will be converted to a timer tick value during generation and can later on accessed via the OsConstName. The conversation is done by rounding time values to the nearest fitting tick value.
        float OsTimeValue: set at pre-compile  # This parameter contains the value of the constant in seconds.
        string OsConstName: set at pre-compile  # The name which is accessed by the application to get the above OsTimeValue.
    container OsEvent [0..*]  # Representation of OS events in the configuration context. Adopted from the OSEK OIL specification.
      integer OsEventMask [0..1]: set at pre-compile  # If event mask would be set to AUTO in OIL, this parameter should be omitted here.
    container OsIsr [0..*]  # The OsIsr container represents an OSEK interrupt service routine.
      enumeration OsIsrCategory: {CATEGORY_1, CATEGORY_2}, set at pre-compile  # This attribute specifies the category of this ISR.
      reference OsIsrResourceRef [0..*]: set at pre-compile, destination=OsResource  # This reference defines the resources accessed by this ISR.
      container OsIsrTimingProtection [0..1]  # This container contains all parameters which are related to timing protection If the container exists, the timing protection is used for this interrupt. If the container does not exist, the interrupt is not supervised regarding timing violations.
        float OsIsrAllInterruptLockBudget [0..1]: set at pre-compile  # This parameter contains the maximum time for which the ISR is allowed to lock all interrupts (via SuspendAllInterrupts() or DisableAllInterrupts()) (in seconds).
        float OsIsrExecutionBudget [0..1]: set at pre-compile  # The parameter contains the maximum allowed execution time of the interrupt (in seconds).
        float OsIsrOsInterruptLockBudget [0..1]: set at pre-compile  # This parameter contains the maximum time for which the ISR is allowed to lock all Category 2 interrupts (via SuspendOSInterrupts()) (in seconds).
        float OsIsrTimeFrame [0..1]: set at pre-compile  # This parameter contains the minimum inter-arrival time between successive interrupts (in seconds).
        container OsIsrResourceLock [0..*]  # This parameter contains a list of times the interrupt uses resources.
          float OsIsrResourceLockBudget: set at pre-compile  # This parameter contains the maximum time the interrupt is allowed to hold the given resource (in seconds).
          reference OsIsrResourceLockResourceRef: set at pre-compile, destination=OsResource  # Reference to the resource the locking time is depending on
    container OsOS  # OS is the object used to define OSEK OS properties for an OSEK application. Per CPU exactly one OS object has to be defined.
      boolean OsStackMonitoring: set at pre-compile  # Select stack monitoring of Tasks/Category 2 ISRs true: Stacks are monitored false: Stacks are not monitored
      boolean OsUseGetServiceId: set at pre-compile  # As defined by OSEK
      boolean OsUseParameterAccess: set at pre-compile  # As defined by OSEK
      boolean OsUseResScheduler: set at pre-compile, default-value=true  # The OsUseResScheduler attribute defines whether the resource RES_SCHEDULER is used within the application.
      enumeration OsScalabilityClass [0..1]: {SC1, SC2, SC3, SC4}, set at pre-compile  # A scalability class for each System Object "OS" has to be selected. In order to customize the operating system to the needs of the user and to take full advantage of the processor features the operating system can be scaled according to the scalability classes. If the scalability class is omitted this translates to the OIL AUTO mechanism.
      enumeration OsStatus: {EXTENDED, STANDARD}, set at pre-compile  # The Status attribute specifies whether a system with standard or extended status has to be used. Automatic assigment is not supported for this attribute.
      container OsHooks  # Container to structure all hooks belonging to the OS
        boolean OsErrorHook: set at pre-compile  # Error hook as defined by OSEK true: Hook is called false: Hook is not called
        boolean OsPostTaskHook: set at pre-compile  # Post-task hook as defined by OSEK true: Hook is called false: Hook is not called
        boolean OsPreTaskHook: set at pre-compile  # Pre-task hook as defined by OSEK true: Hook is called false: Hook is not called
        boolean OsProtectionHook [0..1]: set at pre-compile  # Switch to enable/disable the call to the (user supplied) protection hook. true: Protection hook is called on protection error false: Protection hook is not called
        boolean OsShutdownHook: set at pre-compile  # Shutdown hook as defined by OSEK true: Hook is called false: Hook is not called
        boolean OsStartupHook: set at pre-compile  # Startup hook as defined by OSEK true: Hook is called false: Hook is not called
    container OsResource [0..*]  # An OsResource object is used to co-ordinate the concurrent access by tasks and ISRs to a shared resource, e.g. the scheduler, any program sequence, memory or any hardware area.
      enumeration OsResourceProperty: {INTERNAL, LINKED, STANDARD}, set at pre-compile  # This specifies the type of the resource.
      reference OsResourceAccessingApplication [0..*]: set at pre-compile, destination=OsApplication  # Reference to applications which have an access to this object.
      reference OsResourceLinkedResourceRef [0..1]: set at pre-compile, destination=OsResource  # The link to the resource. Must be valid if OsResourceProperty is LINKED. If OsResourceProperty is not LINKED the value is ignored.
    container OsScheduleTable [0..*]  # An OsScheduleTable addresses the synchronization issue by providing an encapsulation of a statically defined set of alarms that cannot be modified at runtime.
      boolean OsScheduleTableRepeating: set at pre-compile  # true: first expiry point on the schedule table shall be processed at final expiry point delay ticks after the final expiry point is processed. false: the schedule table processing stops when the final expiry point is processed.
      integer OsScheduleTableDuration  # This parameter defines the modulus of the schedule table (in ticks).
      reference OsSchTblAccessingApplication [0..*]: set at pre-compile, destination=OsApplication  # Reference to applications which have an access to this object.
      reference OsScheduleTableCounterRef: set at pre-compile, destination=OsCounter  # This parameter contains a reference to the counter which drives the schedule table.
      container OsScheduleTableAutostart [0..1]  # This parameter specifies if and how the schedule table is started on startup of the Operating System. The options to start a schedule table correspond to the API calls to start schedule tables during runtime.
        enumeration OsScheduleTableAutostartType: {ABSOLUTE, RELATIVE, SYNCHRON}, set at pre-compile  # This specifies the type of the autostart for the schedule table.
        integer OsScheduleTableAbsValue: set at pre-compile  # Absolute autostart tick value when the schedule table starts. Only used if the OsScheduleTableAutostartType is ABSOLUTE.
        integer OsScheduleTableRelOffset: set at pre-compile  # Relative offset in ticks when the schedule table starts. Only used if the OsScheduleTableAutostartType is RELATIVE.
        reference OsScheduleTableAppModeRef [1..*]: set at pre-compile, destination=OsAppMode  # Reference in which application modes the schedule table should be started during startup
      container OsScheduleTableExpiryPoint [1..*]  # The point on a Schedule Table at which the OS activates tasks and/or sets events
        integer OsScheduleTblExpPointOffset: set at pre-compile  # The offset from zero (in ticks) at which the expiry point is to be processed.
        container OsScheduleTableEventSetting [0..*]  # Event that is triggered by that schedule table.
          reference OsScheduleTableSetEventRef: set at pre-compile, destination=OsEvent  # Reference to event that will be set by action
          reference OsScheduleTableSetEventTaskRef: set at pre-compile, destination=OsTask
        container OsScheduleTableTaskActivation [0..*]  # Task that is triggered by that schedule table.
          reference OsScheduleTableActivateTaskRef: set at pre-compile, destination=OsTask  # Reference to task that will be activated by action
        container OsScheduleTblAdjustableExpPoint [0..1]  # Adjustable expiry point
          integer OsScheduleTableMaxAdvance: set at pre-compile  # The maximum positive adjustment that can be made to the expiry point offset (in ticks).
          integer OsScheduleTableMaxRetard: set at pre-compile  # The maximum negative adjustment that can be made to the expiry point offset (in ticks).
      container OsScheduleTableSync [0..1]  # This parameter specifies the synchronization parameters of the schedule table.
        enumeration OsScheduleTblSyncStrategy: {EXPLICIT, IMPLICIT, NONE}, set at pre-compile, origin=AUTOSAR ECUC, default-value=NONE  # AUTOSAR OS provides support for synchronisation in two ways: explicit and implicit.
        integer OsScheduleTblExplicitPrecision [0..1]: set at pre-compile  # This configuration is only valid if the explicit synchronisation is used.
    container OsTask [0..*]  # This container represents an OSEK task.
      enumeration OsTaskSchedule: {FULL, NON}, set at pre-compile  # The OsTaskSchedule attribute defines the preemptability of the task. If this attribute is set to NON, no internal resources may be assigned to this task.
      integer OsTaskActivation: set at pre-compile  # This attribute defines the maximum number of queued activation requests for the task. A value equal to "1" means that at any time only a single activation is permitted for this task. Note that the value must be a natural number starting at 1.
      integer OsTaskPriority: set at pre-compile  # The priority of a task is defined by the value of this attribute. This value has to be understood as a relative value, i.e. the values show only the relative ordering of the tasks. OSEK OS defines the lowest priority as zero (0); larger values correspond to higher priorities.
      reference OsTaskAccessingApplication [0..*]: set at pre-compile, destination=OsApplication  # Reference to applications which have an access to this object.
      reference OsTaskEventRef [0..*]: set at pre-compile, destination=OsEvent  # This reference defines the list of events the extended task may react on.
      reference OsTaskResourceRef [0..*]: set at pre-compile, destination=OsResource  # This reference defines a list of resources accessed by this task.
      container OsTaskAutostart [0..1]  # This container determines whether the task is activated during the system start-up procedure or not for some specific application modes. If the task shall be activated during the system start-up, this container is present and holds the references to the application modes in which the task is auto-started.
        reference OsTaskAppModeRef [1..*]: set at pre-compile, destination=OsAppMode  # Reference to application modes in which that task is activated on startup of the OS
      container OsTaskTimingProtection [0..1]  # This parameter contains all parameters regarding timing protection of the task.
        float OsTaskAllInterruptLockBudget [0..1]: set at pre-compile  # This parameter contains the maximum time for which the task is allowed to lock all interrupts (via SuspendAllInterrupts() or DisableAllInterrupts()) (in seconds).
        float OsTaskExecutionBudget [0..1]: set at pre-compile  # This parameter contains the maximum allowed execution time of the task (in seconds).
        float OsTaskOsInterruptLockBudget [0..1]: set at pre-compile  # This parameter contains the maximum time for which the task is allowed to lock all Category 2 interrupts (via SuspendOSInterrupts()) (in seconds).
        float OsTaskTimeFrame [0..1]: set at pre-compile  # The minimum inter-arrival time between activations and/or releases of a task (in seconds).
        container OsTaskResourceLock [0..*]  # This parameter contains the worst case time between getting and releasing a given resource (in seconds).
          float OsTaskResourceLockBudget: set at pre-compile  # This parameter contains the maximum time the task is allowed to lock the resource (in seconds)
          reference OsTaskResourceLockResourceRef: set at pre-compile, destination=OsResource  # Reference to the resource used by the task
  module definition PduR [0..1]: variants pre-compile/post-build  # Configuration of the PduR (PDU Router) module.
    container PduRGeneral  # This container is a subcontainer of PduR and specifies the general configuration parameters of the PDU Router.
      boolean PduRCanIfSupport: set at pre-compile  # Configuration parameter to enable or disable PDU Router support for CAN interface.
      boolean PduRCanTpSupport: set at pre-compile  # Configuration parameter to enable or disable PDU Router support for CAN TP.
      boolean PduRComSupport: set at pre-compile  # Configuration parameter to enable or disable PDU Router support for COM.
      boolean PduRDcmSupport: set at pre-compile  # Configuration parameter to enable or disable PDU Router support for DCM.
      boolean PduRDevErrorDetect: set at pre-compile  # Switches the Development Error Detection and Notification ON or OFF.
      boolean PduRFifoTxBufferSupport: set at pre-compile  # Configuration parameter to enable or disable PDU Router support for FIFOs as PDU transmit buffers; if PDUR_GATEWAY_OPERATION is disabled, this parameter has to be disabled.
      boolean PduRFrIfSupport: set at pre-compile  # Configuration parameter to enable or disable PDU Router support for FlexRay interface.
      boolean PduRFrTpSupport: set at pre-compile  # Configuration parameter to enable or disable PDU Router support for FlexRay TP.
      boolean PduRGatewayOperation: set at pre-compile  # Configuration parameter to enable or disable PDU Router gateway operation; if PDUR_ZERO_COST_OPERATION is enabled, this parameter has to be disabled.
      boolean PduRIPduMSupport: set at pre-compile  # Configuration parameter to enable or disable PDU Router support for IPDUM; if PDUR_ZERO_COST_OPERATION is enabled, this parameter has to be disabled.
      boolean PduRLinIfSupport: set at pre-compile  # Configuration parameter to enable or disable PDU Router support for LIN interface.
      boolean PduRLinTpSupport: set at pre-compile  # Configuration parameter to enable or disable PDU Router support for LIN TP.
      boolean PduRMulticastFromIfSupport: set at pre-compile  # Configuration parameter to enable or disable PDU Router support for multicasts from an interface module to upper layer modules or lower layer interface modules; if PDUR_ZERO_COST_OPERATION is enabled, this parameter has to be disabled.
      boolean PduRMulticastFromTpSupport: set at pre-compile  # Configuration parameter to enable or disable PDU Router support for multicasts from a TP module to upper layer modules or lower layer TP modules; if PDUR_ZERO_COST_OPERATION is enabled, this parameter has to be disabled.
      boolean PduRMulticastToIfSupport: set at pre-compile  # Configuration parameter to enable or disable PDU Router support for multicasts from an upper layer module to interface modules; if PDUR_ZERO_COST_OPERATION is enabled, this parameter has to be disabled.
      boolean PduRMulticastToTpSupport: set at pre-compile  # Configuration parameter to enable or disable PDU Router support for multicasts from an upper layer module to TP modules; if PDUR_ZERO_COST_OPERATION is enabled, this parameter has to be disabled.
      boolean PduRSbTxBufferSupport: set at pre-compile  # Configuration parameter to enable or disable PDU Router support for single buffers as PDU transmit buffers; if PDUR_GATEWAY_OPERATION is disabled, this parameter has to be disabled.
      boolean PduRVersionInfoApi: set at pre-compile  # Activates/Deactivates the Version Info API.
      boolean PduRZeroCostOperation: set at pre-compile  # All routing paths are implicitly defined and the communication modules directly above or below the PDU Router shall directly call each other without using PDU Router functions (zero cost operation). The configuration parameters PDUR_SINGLE_IF and PDUR_SINGLE_TP are used to specify the related lower layer module.
      enumeration PduRMinimumRoutingLoModule [0..1]: {CAN_IF, CAN_TP, FR_IF, FR_TP, LIN_IF, LIN_TP}, set at link  # Lower layer module to be used for minimum routing; this parameter shall be used if PDUR_ZERO_COST_OPERATION is disabled; otherwise it shall not be used.
      enumeration PduRMinimumRoutingUpModule [0..1]: {COM, DCM}, set at link  # Upper layer module to be used for minimum routing; this parameter shall be used if PDUR_ZERO_COST_OPERATION is disabled; otherwise it shall not be used.
      enumeration PduRSingleIf [0..1]: {CAN_IF, FR_IF, LIN_IF}, set at pre-compile  # Single interface module in case zero cost operation is enabled (PDUR_ZERO_COST_OPERATION).
      enumeration PduRSingleTp [0..1]: {CAN_TP, FR_TP, LIN_TP}, set at pre-compile  # Single transport protocol module in case zero cost operation is enabled (PDUR_ZERO_COST_OPERATION).
      integer PduRMemorySize: set at pre-compile  # Memory size reserved for PDU Router buffers. Only required for gateway operation.
      integer PduRMinimumRoutingLoRxPduId [0..1]: 0..65535, set at link  # Receive PDU identifier of the lower layer module which shall be used at the PDU Router interface to the lower layer module specified by PDUR_MINIMUM_ROUTING_LO_MODULE for minimum routing; this parameter shall be used if PDUR_ZERO_COST_OPERATION is disabled; otherwise it shall not be used.
      integer PduRMinimumRoutingLoTxPduId [0..1]: 0..65535, set at link  # Transmit PDU identifier of the lower layer module which shall be used at the PDU Router interface to the lower layer module specified by PDUR_MINIMUM_ROUTING_LO_MODULE for minimum routing; this parameter shall be used if PDUR_ZERO_COST_OPERATION is disabled; otherwise it shall not be used.
      integer PduRMinimumRoutingUpRxPduId [0..1]: 0..65535, set at link  # Receive PDU identifier of the upper layer module which shall be used at the PDU Router interface to the upper layer module specified by PDUR_MINIMUM_ROUTING_UP_MODULE for minimum routing; this parameter shall be used if PDUR_ZERO_COST_OPERATION is disabled; otherwise it shall not be used.
      integer PduRMinimumRoutingUpTxPduId [0..1]: 0..65535, set at link  # Transmit PDU identifier of the upper layer module which shall be used at the PDU Router interface to the upper layer module specified by PDUR_MINIMUM_ROUTING_UP_MODULE for minimum routing; this parameter shall be used if PDUR_ZERO_COST_OPERATION is disabled; otherwise it shall not be used.
    container PduRGlobalConfig: multiple-configuration-container=true  # This container contains the global configuration parameter of the PduR. It is a MultipleConfigurationContainer, i.e. this container and its sub-containers exit once per configuration set.
      integer PduRConfigurationId [0..1]: set at post-build  # unique configuration identifier of post-build time configuration; this parameter shall be used if PDUR_ZERO_COST_OPERATION is disabled; otherwise it shall not be used.
      container PduRRoutingTable  # PDU Router routing table is a subcontainer ofPduR. This container shall only be considered by the PDU Router Configuration Generator if PduRGeneral/PDUR_ZERO_COST_OPERATION is disabled.
        container PduRRoutingPath [0..*]  # This container is a subcontainer of PduRRoutingTable and specifies the routing path of a PDU.
          integer SduLength [0..1]: 0..255, set at post-build  # Length of PDU data (SDU). Only required if a TX buffer is configured.
          integer TpChunkSize [0..1]: 1..65535, set at post-build  # Chunk size for routing on the fly. Defines the number of bytes which shall be received before transmission on the destination bus may start. Only required for TP gateway PDUs. The TpChunkSize shall not be larger than the length of the related TP Buffer.
          container PduRDefaultValue [0..1]  # This container is a subcontainer of PduRRoutingPath and specifies the default value of the I-PDU. Only required for gateway operation and if at least one PDU specified by PduRDestPdu uses TriggerTransmit Data provision. Represented as an array of IntegerParamDef.
            container PduRDefaultValueElement [0..*]  # Each value element is represented by the element and the position in an array.
              integer DefaultValueElement [1..*]: 0..255, set at post-build  # The default value consists of a number of elements. Each element is one byte long and the number of elements is specified by SduLength. The position of this parameter in the container is specified by the ElementBytePosition parameter.
              integer ElementBytePosition: set at post-build  # This parameter specifies the byte position of the element within the default value
          container PduRDestPdu [1..*]  # This container is a subcontainer of PduRRoutingPath and specifies one destination for the PDU to be routed.
            enumeration DataProvision [0..1]: {DIRECT, TRIGGER_TRANSMIT}, set at post-build  # Specifies how data are provided: direct (as part of the Transmit call) or via the TriggerTransmit callback function. Only required for non-TP gateway PDUs.
            reference DestPduRef: set at pre-compile in variant pre-compile / post-build in variant post-build, destination=Pdu  # Destination PDU reference; reference to unique PDU identifier which shall be used by the PDU Router instead of the source PDU ID when calling the related function of the destination module.
            reference TxBufferRef [0..1]: set at post-build, destination=PduRTxBuffer  # Specifies the assigned transmit buffer. Only required for specific non-TP gateway PDUs.
          container PduRSrcPdu  # This container is a subcontainer of PduRRoutingPath and specifies the source of the PDU to be routed.
            integer HandleId: 0..65535, set at pre-compile in variant pre-compile / post-build in variant post-build, symbolic-name-value=true  # PDU identifier assigned by PDU Router.
            reference SrcPduRef: set at pre-compile in variant pre-compile / post-build in variant post-build, destination=Pdu  # Source PDU reference; reference to unique PDU identifier which shall be used for the requested PDU Router operation.
      container PduRTpBufferTable [0..1]  # This container is a subcontainer of PduR and contains the definition of all TP buffers (only required for PDU Router gateway operation). This container shall only be considered by the PDU Router Configuration Generator if PduRGeneral/PDUR_GATEWAY_OPERATION is enabled.
        integer PduRMaxTpBufferNumber: 0..65535, set at pre-compile  # maximum number of TP buffers.
        container PduRTpBuffer [0..*]  # This container is a subcontainer of PduRTpBufferTable and specifies a TP buffer.
          integer Length: 1..65535, set at post-build  # Length of the buffer.
      container PduRTxBufferTable [0..1]  # This container is a subcontainer of PduR and contains the definition of all transmit buffers (used by specific non-TP PDUs; only required for PDU Router gateway operation). This container shall only be considered by the PDU Router Configuration Generator if PduRGeneral/PDUR_GATEWAY_OPERATION is enabled.
        integer PduRMaxTxBufferNumber: 0..65535, set at pre-compile  # maximum number of transmit buffers
        container PduRTxBuffer [0..*]  # This container is a subcontainer of PduRTxBufferTable and specifies a transmit buffer for a non-TP PDU.
          integer Depth: 0..255, set at post-build  # Specifies the depth of the buffer
          integer Length: 1..255, set at post-build  # Length of the buffer.
  module definition Port [0..1]: variants pre-compile/post-build  # Configuration of the Port module.
    container PortConfigSet: multiple-configuration-container=true  # This container is the base of a multiple configuration set
      container PortContainer [1..*]  # Container collecting the PortPins.
        integer PortNumberOfPortPins: set at pre-compile  # The number of specified PortPins in this PortContainer.
        container PortPin [1..*]  # Configuration of the individual port pins.
          boolean PortPinDirectionChangeable: set at pre-compile in variant pre-compile / post-build in variant post-build  # Parameter to indicate if the direction is changeable on a port pin during runtime. true: Port Pin direction changeable enabled. false: Port Pin direction changeable disabled.
          enumeration PortPinDirection: {PORT_PIN_IN, PORT_PIN_OUT}, set at pre-compile in variant pre-compile / post-build in variant post-build  # The initial direction of the pin (IN or OUT). If the direction is not changeable, the value configured here is fixed. The direction must match the pin mode. E.g. a pin used for an ADC must be configured to be an in port. Implementation Type: Port_PinDirectionType
          enumeration PortPinInitialMode: set at pre-compile in variant pre-compile / post-build in variant post-build  # Port pin mode from mode list for use with Port_Init() function.
          enumeration PortPinLevelValue: {PORT_PIN_LEVEL_HIGH, PORT_PIN_LEVEL_LOW}, set at pre-compile in variant pre-compile / post-build in variant post-build  # Port Pin Level value from Port pin list.
          enumeration PortPinMode: {PORT_PIN_MODE_ADC, PORT_PIN_MODE_CAN, PORT_PIN_MODE_DIO, PORT_PIN_MODE_DIO_GPT, PORT_PIN_MODE_DIO_WDG, PORT_PIN_MODE_FLEXRAY, PORT_PIN_MODE_ICU, PORT_PIN_MODE_LIN, PORT_PIN_MODE_MEM, PORT_PIN_MODE_PWM, PORT_PIN_MODE_SPI}, set at pre-compile in variant pre-compile / post-build in variant post-build  # Port pin mode from mode list. Note that more than one mode is allowed by default. That way it is e.g. possible to combine DIO with another mode such as ICU. More HW specific literals may be added by module implementor. E.g. SPI may be further broken down into SpiCsHw, SpiCsSw, etc. if necessary.
          integer PortPinId: 0.., set at pre-compile, symbolic-name-value=true  # Pin Id of the port pin. This value will be assigned to the symbolic name derived from the port pin container short name.
    container PortGeneral  # Module wide configuration parameters of the PORT driver.
      boolean PortDevErrorDetect: set at pre-compile  # Switches the Development Error Detection and Notification on or off. true: Enabled. false: Disabled.
      boolean PortSetPinDirectionApi: set at pre-compile  # Pre-processor switch to enable / disable the use of the function Port_SetPinDirection(). TRUE: Enabled - Function Port_SetPinDirection() is available. FALSE: Disabled - Function Port_SetPinDirection() is not available.
      boolean PortSetPinModeApi: set at pre-compile  # Pre-processor switch to enable / disable the use of the function Port_SetPinMode(). true: Enabled - Function Port_SetPinMode() is available. false: Disabled - Function Port_SetPinMode() is not available.
      boolean PortVersionInfoApi: set at pre-compile  # Pre-processor switch to enable / disable the API to read out the modules version information. true: Version info API enabled. false: Version info API disabled.
  module definition Pwm [0..*]: variants pre-compile/post-build  # Configuration of Pwm (Pulse Width Modulation) module.
    container PwmChannelConfigSet: multiple-configuration-container=true  # Multiple Configuration Set Container
      container PwmChannel [1..*]  # Configuration of an individual PWM channel.
        enumeration PwmChannelClass: {PWM_FIXED_PERIOD, PWM_FIXED_PERIOD_SHIFTED, PWM_VARIABLE_PERIOD}, set at pre-compile in variant pre-compile / post-build in variant post-build  # Class of PWM Channel. ImplementationType: Pwm_ChannelClassType
        enumeration PwmIdleState: {PWM_HIGH, PWM_LOW}, set at pre-compile in variant pre-compile / post-build in variant post-build  # The parameter PWM_IDLE_STATE represents the output state of the PWM after the signal is stopped (e.g. call of Pwm_SetOutputToIdle).
        enumeration PwmPolarity: {PWM_HIGH, PWM_LOW}, set at pre-compile in variant pre-compile / post-build in variant post-build  # Defines the starting polarity of each PWM channel.
        float PwmPeriodDefault: 0.0.., set at pre-compile in variant pre-compile / post-build in variant post-build  # Value of period used for Initialization.(in seconds).
        function name PwmNotification: set at pre-compile in variant pre-compile / post-build in variant post-build, default-value="NULL"  # Definition of the Callback function.
        integer PwmChannelId: 0.., set at pre-compile, symbolic-name-value=true  # Channel Id of the PWM channel. This value will be assigned to the symbolic name derived of the PwmChannel container short name.
        integer PwmDutycycleDefault: 0..32768, set at pre-compile in variant pre-compile / post-build in variant post-build  # Value of duty cycle used for Initialization 0, represents 0% 0x8000 represents 100%
    container PwmConfigurationOfOptApiServices
      boolean PwmDeInitApi: set at pre-compile  # Adds / removes the service Pwm_DeInit() from the code.
      boolean PwmGetOutputState: set at pre-compile
      boolean PwmSetDutyCycle: set at pre-compile
      boolean PwmSetOutputToIdle: set at pre-compile
      boolean PwmSetPeriodAndDuty: set at pre-compile
      boolean PwmVersionInfoApi: set at pre-compile  # Switch to indicate that the Pwm_ GetVersionInfo is supported
    container PwmGeneral
      boolean PwmDevErorDetect: set at pre-compile  # Switch for enabling the development error detection.
      boolean PwmDutycycleUpdatedEndperiod: set at pre-compile  # Switch for enabling the update of the duty cycle parameter at the end of the current period
      boolean PwmNotificationSupported: set at pre-compile  # Switch to indicate that the notifications are supported
      boolean PwmPeriodUpdatedEndperiod: set at pre-compile  # Switch for enabling the update of the period parameter at the end of the current period
      integer PwmIndex: set at pre-compile  # Specifies the InstanceId of this module instance. If only one instance is present it shall have the Id 0.
  module definition RamTst [0..1]: variants pre-compile/link-time  # Configuration of the RamTst module.
    container RamTstCommon  # This container holds a list of all available functions in the RamTst module. Each function is turned ON or OFF before compiling so that only the desired test algorithms are in the compiled code.
      boolean RamTstAllowApi: set at pre-compile  # Preprocessor switch to disable / enable the function "RamTst_Allow".
      boolean RamTstChangeMaxNumOfTestedCellsA: set at pre-compile  # Preprocessor switch to disable / enable the function "RamTst_ChangeMaxNumberOfTestedCells".
      boolean RamTstChangeNumOfTestedCellsApi: set at pre-compile  # Preprocessor switch to disable / enable the function "RamTst_ChangeNumberOfTestedCells"
      boolean RamTstChangeTestAlgorithmApi: set at pre-compile  # Preprocessor switch to disable / enable the function "RamTst_ChangeTestAlgorithm"
      boolean RamTstDevErrorDetect: set at pre-compile  # Preprocessor switch to select the development error tracer (DET) ON or OFF
      boolean RamTstGetExecutionStatusApi: set at pre-compile  # Preprocessor switch to disable / enable the function "RamTst_GetExecutionStatus"
      boolean RamTstGetNumberOfTestedCellsApi: set at pre-compile  # Preprocessor switch to disable / enable the function "RamTst_GetNumberOfTestedCells"
      boolean RamTstGetTestAlgorithmApi: set at pre-compile  # Preprocessor switch to disable / enable the function "RamTst_GetTestAlgorithm"
      boolean RamTstGetTestResultApi: set at pre-compile  # Preprocessor switch to disable / enable the function "RamTst_GetTestResult"
      boolean RamTstGetTestResultPerBlockApi: set at pre-compile  # Preprocessor switch to disable / enable the function "RamTst_GetTestResultPerBlock"
      boolean RamTstGetVersionInfoApi: set at pre-compile  # Preprocessor switch to disable / enable the function "RamTst_GetVersionInfo"
      boolean RamTstResumeApi: set at pre-compile  # Preprocessor switch to disable / enable the function "RamTst_Resume".
      boolean RamTstStopApi: set at pre-compile  # Preprocessor switch to disable / enable the function "RamTst_Stop"
      boolean RamTstSuspendApi: set at pre-compile  # Preprocessor switch to disable / enable the function "RamTst_Suspend".
      container RamTstAlgorithms  # This container holds all of the available test algorithms for the specific microcontroller. Each test algorithm is selected ON or OFF before compiling so that only the desired test algorithms are in the compiled code.
        boolean RamTstAbrahamTestSelected: set at pre-compile  # Preprocessor switch to select the Abraham Test ON or OFF
        boolean RamTstCheckerboardTestSelected: set at pre-compile  # Preprocessor switch to select the Checkerboard Test ON or OFF
        boolean RamTstGalpatTestSelected: set at pre-compile  # Preprocessor switch to select the Galpat Test ON or OFF
        boolean RamTstMarchTestSelected: set at pre-compile  # Preprocessor switch to select the March Test ON or OFF
        boolean RamTstTranspGalpatTestSelected: set at pre-compile  # Preprocessor switch to select the Transparent Galpat Test ON or OFF
        boolean RamTstWalkPathTestSelected: set at pre-compile  # Preprocessor switch to select the Walking Path Test ON or OFF
      container RamTstConfigParams  # This container specifies configuration parameters which are set at pre-compile or link time. The multiplicity of the included container depends on the pre-compile configuration in the container "RamTst_Algorithms".
        derived integer RamTstNumberOfAlgorithms: set at link in variant link-time / pre-compile in variant pre-compile, calculation-formula=count of the container ramtst_algparams, calculation-language=INFORMAL  # Number of configured algorithms in the container "RamTst_Algorithms" calculationFormula = count of the container RamTst_AlgParams
        enumeration RamTstDefaultTestAlgorithm: {RAMTST_ABRAHAM_TEST, RAMTST_CHECKERBOARD_TEST, RAMTST_GALPAT_TEST, RAMTST_MARCH_TEST, RAMTST_MOD_HAMMINGCODE_TEST, RAMTST_TRANSP_GALPAT_TEST, RAMTST_WALK_PATH_TEST}, set at link in variant link-time / pre-compile in variant pre-compile  # This is the default algorithm after the "RamTst_Init(..)" function. This is the initial value for a RAM variable which could be changed by the function "RamTst_ChangeTestAlgorithm"
        function name RamTstTestCompletedNotification: set at link in variant link-time / pre-compile in variant pre-compile  # This function will be called after finishing the RAM test without an error.
        function name RamTstTestErrorNotification: set at link in variant link-time / pre-compile in variant pre-compile  # This function will be called if an error occurs during the RAM test.
        integer RamTstMinNumberOfTestedCells: set at link in variant link-time / pre-compile in variant pre-compile  # Minimum number of tested cells, as defined by implementer.
        container RamTstAlgParams [1..*]  # This container holds parameters for configuring an algorithm. Each algorithm selected in the RamTst_Algorithms container has a corresponding RamTstAlgParams container. The multiplicity of the included container depends on the number of separate blocks of RAM which are defined for the particular algorithm.
          derived integer RamTstNumberOfBlocks: set at link in variant link-time / pre-compile in variant pre-compile, calculation-formula=count of enabled ramtstblockparams for this algorithm id., calculation-language=INFORMAL  # Number of RAM blocks configured using the container "RamTst_BlockParams" calculationFormula = Count of enabled RamTstBlockParams for this algorithm ID.
          integer RamTstAlgorithmId: set at link in variant link-time / pre-compile in variant pre-compile  # This is the algorithm ID
          integer RamTstExtNumberOfTestedCells: set at link in variant link-time / pre-compile in variant pre-compile  # This is the absolute maximum value for the number of cells that NUMBER_OF_TESTED_CELLS and MAX_NUMBER_OF_TESTED_CELLS can be.
          integer RamTstMaxNumberOfTestedCells: set at link in variant link-time / pre-compile in variant pre-compile  # This is the initial value for a RAM variable, which can be changed by the function "RamTst_ChangeMaxNumberOfTestedCells".
          integer RamTstNumberOfTestedCells: set at link in variant link-time / pre-compile in variant pre-compile  # This is the initial value for a RAM variable, which can be changed by the function "RamTst_ChangeNumberOfTestedCells"
          container RamTstBlockParams [1..*]  # This container holds the description for one block of RAM. For each RAM block to be tested by a given algorithm, there is one container which describes the block. Multiple instances of this container are included in RamTst_AlgParams for each algorithm selected in RamTst_Algorithms.
            integer RamTstBlockId: set at link in variant link-time / pre-compile in variant pre-compile  # ID of the RAM block
            integer RamTstEndAddress: set at link in variant link-time / pre-compile in variant pre-compile  # End Address of the RAM block
            integer RamTstStartAddress: set at link in variant link-time / pre-compile in variant pre-compile  # Start Address of the RAM block
  module definition Rte [0..1]: variants pre-compile  # Configuration of the Rte (Runtime Environment) module.
    container ComponentTypeCalibration [0..*]  # Specifies for each CalprmComponentType or AtomicSoftwareComponentType whether calibration is enabled.
      boolean CalibrationSupportEnabled: set at pre-compile  # Enables calibration support for the specified CalprmComponentType or AtomicSoftwareComponentType.
      foreign reference ComponentTypeRef: set at pre-compile, destination-type=ComponentType  # Reference to the CalprmComponentType or AtomicSoftwareComponentType.
    container RteGeneration  # This container holds the parameters for the configuration of the RTE Generation.
      boolean RteMeasurementSupport: set at pre-compile  # The RTE generator shall have the option to switch off support for measurement for generated RTE code. This option shall influence complete RTE code at once.
      enumeration RteCalibrationSupport: {DOUBLE_POINTERED, INITIALIZED_RAM, NONE, SINGLE_POINTERED}, set at pre-compile  # The RTE generator shall have the option to switch off support for calibration for generated RTE code. This option shall influence complete RTE code at once.
      enumeration RteGenerationMode: {COMPATIBILITY_MODE, VENDOR_MODE}, set at pre-compile  # Switch between the two available generation modes of the RTE generator.
      enumeration RteOptimizationMode: {MEMORY, RUNTIME}, set at pre-compile  # Switch between the two available optimization modes of the RTE generator.
      function name RteVfbTraceFunction [0..*]: set at pre-compile  # The RTE generator shall enable VFB tracing for a given hook function when there is a #define in the RTE configuration header file for the hook function name and tracing is globally enabled. Example: #define Rte_WriteHook_i1_p1_a_Start
      integer RteVfbTrace: set at pre-compile  # The RTE generator shall globally enable VFB tracing when RTE_VFB_TRACE is defined in the RTE configuration header file as a non-zero integer. The RTE generator shall globally disable VFB tracing when RTE_VFB_TRACE is defined in the RTE configuration header file as 0.
    container SwComponentInstance [1..*]  # Representation of one SW-Component instance located on the to be configured ECU. All subcontainer configuration aspects are in relation to this SW-Component instance. The SwComponentInstance can be either an ApplicationSoftwareComponenInstance or a ServiceComponentInstance.
      foreign reference ImplementationRef [0..1]: set at pre-compile, destination-type=SwcImplementation  # The Implementation which is assiged to the ComponentPrototype.
      foreign reference ServiceComponentPrototypeRef [0..1]: destination-type=ServiceComponentPrototype  # Reference to the ServiceComponentPrototype representing an particular service on this ECU. If ServiceComponentPrototypeRef is specified there shall not be the SoftwareComponentInstanceRef specified.
      instance reference SoftwareComponentInstanceRef [0..1]: set at pre-compile, destination-context=ComponentPrototype*, destination-type=ComponentPrototype  # Reference to a SW-Component ComponentPrototype. If SoftwareComponentInstanceRef is specified there shall not be the ServiceComponentPrototypeRef specified. Semantic Constraint: Only ComponentPrototypes which have an AtomicSoftwareComponentType as <<isOfType>> shall be referenced here.
      container ExclusiveAreaImplementation [0..*]  # Specifies the implementation to be used for the data consistency of this ExclusiveArea.
        enumeration ExclusiveAreaImplMechanism: {COOPERATIVE_RUNNABLE_PLACEMENT, INTERRUPT_BLOCKING, NON_PREEMPTIVE_TASK, OS_RESOURCE}, set at pre-compile  # To be used implementation mechanism for the specified ExclusiveArea.
        foreign reference ExclusiveAreaRef: set at pre-compile, destination-type=ExclusiveArea  # Reference to the ExclusiveArea.
      container NVRamAllocation [0..*]  # Specifies the relationship between the SW-Components NVRAMMapping / NVRAM needs and the NvM module configuration.
        linker symbol def RamBlockLocationSymbol: lower-multiplicity=0, upper-multiplicity=1, set at pre-compile  # This is the name of the linker object name where the NVRam Block will be mirrored by the Nvm. This symbol will be resolved into the parameter "NvmRamBlockDataAddress" from the "NvmBlockDescriptor".
        linker symbol def RomBlockLocationSymbol: lower-multiplicity=0, upper-multiplicity=1, set at pre-compile  # This is the name of the linker object name where the NVRom Block will be accessed by the Nvm. This symbol will be resolved into the parameter "NvmRomBlockDataAddress" from the "NvmBlockDescriptor".
        instance reference SwNvRamMappingReference: set at pre-compile, destination-context=ComponentPrototype*, destination-type=NVRAMMapping  # Reference to the NVRAMMapping instance to be configured.
        symbolic name reference NvmBlockRef: destination=NvmBlockDescriptor  # Reference to the used NvM block for storage of the NVRAMMapping information.
      container RunnableEntityMapping [0..*]  # Maps a RunnableEntity onto one OS Task based on the activating RTEEvent. Even if a RunnableEntity is executed in the caller's context this RunnableEntityMapping shall be specified, but no MappedToTask and PositionInTask elements given.
        float ActivationOffset [0..1]: set at pre-compile  # Activation offset in seconds.
        integer PositionInTask [0..1]: set at pre-compile  # Each RunnableEntities mapped to an OsTask has a specific position within the task execution. For periodic activation this is the order of execution. For event driver activation this is the order of evaluation which actual RunnableEntity has to be executed.
        foreign reference RTEEventRef: set at pre-compile, destination-type=RTEEvent  # Reference to the description of the RTEEvent which is pointing to the RunnableEntity being mapped. This allows a fine grained mapping of RunnableEntites based on the activating RTEEvent.
        reference MappedToTaskRef [0..1]: set at pre-compile, destination=OsTask  # Reference to the OsTask the RunnableEntity is mapped to. If no reference to the OsTask is specified the RunnableEntity is executed in the context of the caller.
        reference UsedOsEventRef [0..1]: set at pre-compile, destination=OsEvent  # If an OsEvent is used to activate the RunnableEntity it shall be referenced here.
  module definition SchM [0..1]: variants pre-compile  # Configuration of the SchM (BSW Scheduler) module.
    container SchMGeneral  # General configuration parameters of the SchM.
      boolean SchMDevErrorDetect: set at pre-compile  # Switches the Development Error Detection and Notification ON or OFF.
      boolean SchMVersionInfoApi: set at pre-compile  # Switches the service SchM_GetVersionInfo ON or OFF.
    container SchMMainFunctionMapping [1..*]  # Maps a MainFunction onto one OS Task.
      integer SchMPositionInTask: 0..255, set at pre-compile  # The parameter depicts the specific Position of the MainFunction within the OS Task. Note: The dependencies between the main processing functions mapped to the same task have been resolved by the configuration (process) beforehand. The result of this resolution is the order of the main processing functions within this task.
      foreign reference SchMMainFunctionRef: set at pre-compile, destination-type=BswSchedulableEntity  # The parameter depicts the reference to the MainFunction.
      reference SchMMappedToTask: set at pre-compile, destination=OsTask  # The parameter depicts the reference to the OS Task the MainFunction is mapped to. Note: The AUTOSAR OS Task has already been available and is configured. Therefore, the configuration attributes of the task do not need to mention again.
      container SchMScheduleTableMapping [0..*]  # Assigns a MainFunction to a OS Schedule Table
        reference SchMScheduletableRef: set at pre-compile, destination=OsScheduleTable  # The parameter depicts the reference to the OS SchedulaTable the MainFunction is mapped to.
    container SchMModuleConfiguration [0..*]  # Contains module specific configuration items.
      string SchMModuleLiteral: set at pre-compile  # The parameter depicts a symbolic name (a literal) for the unambigous identification of a BSW module; in fact it is the <ModulePrefix> specified for each BSW module in the Basic Software Module List.
      container InstanceConfiguration [1..*]  # Contains instance specific configuration items. One instance of this container for each instance of the module.
        integer SchMInstanceId: 0..255, set at pre-compile  # The parameter depicts a value for the unambigous identification of a BSW module instance.
        string SchMInstanceLiteral: set at pre-compile  # The parameter depicts a symbolic name for the unambigous identification of a BSW module instance.
        container ActivationPointConf [0..*]  # Contains configuration items of ActivationPoints in the context of a BSW module.
          integer SchMActivationId: 0..255, set at pre-compile  # The parameter depicts a value for the unambigous identification of an ActivationPoint.
          string SchMActivationLiteral: set at pre-compile  # The parameter depicts a symbolic name for the unambigous identification of an ActivationPoint.
        container CancelationPointConf [0..*]  # Contains configuration items of CancelationPoints in the context of a BSW module.
          integer SchMCancelationId: 0..255, set at pre-compile  # The parameter depicts a value for the unambigous identification of an CancelationPoint.
          string SchMCancelationLiteral: set at pre-compile  # The parameter depicts a symbolic name for the unambigous identification of a CancelationPoint.
        container ExclusiveAreaConf [0..*]  # Contains configuration items of critical sections (ExclusiveArea) in the context of a BSW module.
          integer SchMExclusiveAreaId: 0..255, set at pre-compile  # The parameter depicts a value for the unambigous identification of an ExclusiveArea.
          string SchMExclusiveAreaLiteral: set at pre-compile  # The parameter depicts a symbolic name for the unambigous identification of an ExclusiveArea.
        container SporadicEventConf [0..*]  # Contains configuration items of SporadicEvents.
          float DelayTime: set at pre-compile  # The parameter depicts the minimum delay time in seconds until a main processing functions shall be activated. This configuration parameter is an input for integration. It represents the base for the real, implementation specific values.
          string SchMSporadicLiteral: set at pre-compile  # The parameter depicts a symbolic name dfor the unambiguous identification of a sporadiv event.
  module definition Spi [0..1]: variants pre-compile/link-time/post-build  # Configuration of the Spi (Serial Peripheral Interface) module.
    container SpiDriver: multiple-configuration-container=true
      integer SpiMaxChannel [0..1]: set at link in variant link-time / pre-compile in variant pre-compile / post-build in variant post-build  # This parameter contains the number of Channels configured. It will be gathered by tools during the configuration stage.
      integer SpiMaxJob [0..1]: set at link in variant link-time / pre-compile in variant pre-compile / post-build in variant post-build
      integer SpiMaxSequence [0..1]: set at link in variant link-time / pre-compile in variant pre-compile / post-build in variant post-build
      container SpiChannel [1..*]  # All data needed to configure one SPI-channel
        enumeration SpiChannelType: {EB, IB}, set at link in variant link-time / pre-compile in variant pre-compile / post-build in variant post-build  # Buffer usage with EB/IB channel
        enumeration SpiTransferStart: {LSB, MSB}, set at link in variant link-time / pre-compile in variant pre-compile / post-build in variant post-build  # This parameter defines the first starting bit for transmission.
        integer SpiChannelId: set at pre-compile, symbolic-name-value=true
        integer SpiDataWidth: 1..32, set at link in variant link-time / pre-compile in variant pre-compile / post-build in variant post-build  # This parameter is the width of a transmitted data unit.
        integer SpiDefaultData: set at link in variant link-time / pre-compile in variant pre-compile / post-build in variant post-build  # This parameter is the default value to transmit.
        integer SpiEbMaxLength: set at link in variant link-time / pre-compile in variant pre-compile / post-build in variant post-build  # This parameter contains the maximum size of data buffers in case of EB Channels and only.
        integer SpiIbNBuffers: set at link in variant link-time / pre-compile in variant pre-compile / post-build in variant post-build  # This parameter contains the maximum number of data buffers in case of IB Channels and only.
      container SpiExternalDevice [1..*]  # The communication settings of an external device. Closely linked to SpiJob.
        boolean SpiEnableCs: set at link in variant link-time / pre-compile in variant pre-compile / post-build in variant post-build  # This parameter enables or not the Chip Select handling functions.
        enumeration SpiCsPolarity: {HIGH, LOW}, set at link in variant link-time / pre-compile in variant pre-compile / post-build in variant post-build  # This parameter defines the active polarity of Chip Select.
        enumeration SpiDataShiftEdge: {LEADING, TRAILING}, set at link in variant link-time / pre-compile in variant pre-compile / post-build in variant post-build  # This parameter defines the SPI data shift edge.
        enumeration SpiShiftClockIdleLevel: {HIGH, LOW}, set at link in variant link-time / pre-compile in variant pre-compile / post-build in variant post-build  # This parameter defines the SPI shift clock idle level.
        float SpiBaudrate: set at link in variant link-time / pre-compile in variant pre-compile / post-build in variant post-build  # This parameter is the communication baudrate - This parameter allows using a range of values, from the point of view of configuration tools, from Hz up to MHz.
        float SpiTimeClk2Cs: 0.0..100.0, set at link in variant link-time / pre-compile in variant pre-compile / post-build in variant post-build  # Timing between clock and chip select - This parameter allows to use a range of values from 0 up to 100 microSec. the real configuration-value used in software BSW-SPI is calculated out of this by the generator-tools
        string SpiCsIdentifier: set at link in variant link-time / pre-compile in variant pre-compile / post-build in variant post-build, symbolic-name-value=true  # This parameter is the symbolic name to identify the Chip Select (CS) allocated to this Job.
      container SpiJob [1..*]  # All data needed to configure one SPI-Job, amongst others the connection between the internal SPI unit and the special settings for an external device is done.
        enumeration SpiHwUnit: {CSIB0, CSIB1, CSIB2, CSIB3}, set at link in variant link-time / pre-compile in variant pre-compile / post-build in variant post-build  # This parameter is the symbolic name to identify the HW SPI Hardware microcontroller peripheral allocated to this Job.
        function name SpiJobEndNotification: set at link in variant link-time / pre-compile in variant pre-compile / post-build in variant post-build  # This parameter is a reference to a notification function.
        integer SpiJobId: set at pre-compile, symbolic-name-value=true
        integer SpiJobPriority: 0..3, set at link in variant link-time / pre-compile in variant pre-compile / post-build in variant post-build  # Priority of the Job
        reference ChannelAssignment [1..*]: set at link in variant link-time / pre-compile in variant pre-compile / post-build in variant post-build, destination=SpiChannel  # A job references several channels.
        reference DeviceAssignment: destination=SpiExternalDevice  # Reference to the external device used by this job
      container SpiSequence [1..*]  # All data needed to configure one SPI-sequence
        boolean SpiInterruptibleSequence: set at link in variant link-time / pre-compile in variant pre-compile / post-build in variant post-build  # This parameter allows or not this Sequence to be suspended by another one.
        function name SpiSeqEndNotification: set at link in variant link-time / pre-compile in variant pre-compile / post-build in variant post-build  # This parameter is a reference to a notification function.
        integer SpiSequenceId: set at pre-compile, symbolic-name-value=true
        reference JobAssignment [1..*]: set at link in variant link-time / pre-compile in variant pre-compile / post-build in variant post-build, destination=SpiJob  # A sequence references several jobs, which are executed during a communication sequence
    container SpiGeneral  # General configuration settings for SPI-Handler
      boolean SpiCancelApi: set at pre-compile  # Switches the Spi_Cancel function ON or OFF.
      boolean SpiDevErrorDetect: set at pre-compile  # Switches the Development Error Detection and Notification ON or OFF.
      boolean SpiHwStatusApi: set at pre-compile  # Switches the Spi_GetHWUnitStatus function ON or OFF.
      boolean SpiInterruptibleSeqAllowed: set at pre-compile  # Switches the Interruptible Sequences handling functionality ON or OFF.
      boolean SpiVersionInfoApi: set at pre-compile  # Switches the Spi_GetVersionInfo function ON or OFF.
      integer SpiChannelBuffersAllowed: 0..2, set at pre-compile  # Selects the SPI Handler/Driver Channel Buffers usage allowed and delivered.
      integer SpiLevelDelivered: 0..2, set at pre-compile  # Selects the SPI Handler/Driver level of scalable functionality that is available and delivered.
  module definition Wdg [0..*]: variants pre-compile/link-time/post-build  # Configuration of the Wdg (Watchdog driver) module. This should be the extern watchdog driver. For internal watchdogs, no port pins / DIO is used.
    container WdgExternalConfiguration  # Configuration items for an external watchdog hardware
      choice reference WdgExternalContainerRef: set at link in variant link-time / pre-compile in variant pre-compile / post-build in variant post-build, destination=[SpiSequence, DioChannelGroup]  # Reference to either - a DioChannelGroup container in case the hardware watchdog is connected via DIO pins - a SpiSequenceConfiguration container in case the watchdog hardware is accessed via SPI
    container WdgGeneral  # All general parameters of the watchdog driver are collected here.
      boolean WdgDevErrorDetect: set at pre-compile  # Compile switch to enable / disable development error detection for this module. True: Development error detection enabled False: Development error detection disabled
      boolean WdgDisableAllowed: set at pre-compile  # Compile switch to allow / forbid disabling the watchdog driver during runtime. True: Disabling the watchdog driver at runtime is allowed. False: Disabling the watchdog driver at runtime is not allowed.
      boolean WdgVersionInfoApi: set at pre-compile  # Compile switch to enable / disable the version information API True: API enabled False: API disables
      function name WdgTriggerLocation: set at pre-compile  # Location (memory address) of the watchdog trigger routine.
      integer WdgIndex: set at pre-compile, symbolic-name-value=true  # Represents the watchdog driver's ID so that it can be referenced by the watchdog interface.
    container WdgModeConfig: multiple-configuration-container=true  # Configuration items for the different watchdog modes
      enumeration WdgDefaultMode: {WDGIF_FAST_MODE, WDGIF_OFF_MODE, WDGIF_SLOW_MODE}, set at post-build in variant link-time+post-build / pre-compile in variant pre-compile  # Default mode for watchdog driver initialization. ImplementationType: WdgIf_ModeType
      container WdgSettingsFast  # Hardware dependent settings for the watchdog driver's "fast" mode.
      container WdgSettingsOff  # Hardware dependent settings for the watchdog driver's "off" mode.
      container WdgSettingsSlow  # Hardware dependent settings for the watchdog driver's "slow" mode.
    container WdgPublishedInformation  # Container holding all Wdg specific published information parameters
      enumeration WdgTriggerMode: {WDG_BOTH, WDG_TOGGLE, WDG_WINDOW}, set at published-information  # Watchdog trigger mode (toggle/window/both)
      float WdgMaxTimeout [0..1]: set at published-information  # Maximum timeout period in [s].
      float WdgMinTimeout [0..1]: set at published-information  # Minimum timeout period in [s].
      float WdgResolution [0..1]: set at published-information  # Resolution of watchdog timeout period in [s].
      container WdgTimeoutList [0..1]  # List of selectable timeout periods in [s].
        float WdgTimeoutPeriod [1..*]: set at published-information  # A single timeout period onto the Wdg can be configured.
  module definition WdgIf [0..1]: variants pre-compile  # Configuration of the WdgIf (Watchdog Interface) module.
    container WdgIfDevice [1..*]
      integer WdgIfDeviceIndex: symbolic-name-value=true  # Represents the watchdog interface ID so that it can be referenced by the watchdog manager.
      symbolic name reference WdgRef: destination=WdgGeneral  # Reference to the watchdog drivers that are controlled by the watchdog interface.
    container WdgIfGeneral  # This container collects all generic watchdog interface parameters.
      boolean WdgIfDevErrorDetect: set at pre-compile  # Pre-processor switch for enabling the development error detection and reporting. true: Development error detection enabled false: Development error detection disabled
      boolean WdgIfVersionInfoApi: set at pre-compile  # Pre-processor switch to enable / disable the service returning the version information. true: Version information service enabled false: Version information service disabled
      integer WdgIfNumberOfDevices: 1..255, set at pre-compile  # Constant specifying the number of controlled watchdog drivers. Minimum number of watchdog drivers shall be one, maximum number limited by type of device index parameter. Can be calculated by counting the no. of references to the watchdog drivers.
  module definition WdgM [0..1]: variants pre-compile/post-build  # Configuration of the WdgM (Watchdog Manager) module.
    container WdgMConfigSet: multiple-configuration-container=true  # This container describes one of multiple configuration sets of WdgM. This is a MultipleConfigurationContainer, i.e. this container and its sub-containers exist once per configuration set.
      symbolic name reference WdgMInitialMode: destination=WdgMMode  # The mode that the Watchdog Manager is in after it has been initialized.
      container WdgMMode [1..255]  # The container describes one of several modes of the Watchdog Manager.
        integer WdgMExpiredSupervisionCycleTol: 0.., set at post-build in variant link-time / pre-compile in variant pre-compile  # This parameter shall be used to define a value that fixes the amount of expired supervision cycles for how long the blocking of watchdog triggering shall be postponed.
        integer WdgMModeId: 0..255, set at post-build in variant link-time / pre-compile in variant pre-compile, symbolic-name-value=true  # This parameter fixes the identfier for the mode. This identifier is for instance passed as a parameter to the WdgM_SetMode service.
        choice container WdgMActivation  # This container allows to choose between Main Function activation and GPT activation.
          container WdgMActivationGpt [0..1]  # GPT activation.
            integer WdgMGptCycle: 1.., set at post-build in variant link-time / pre-compile in variant pre-compile  # This parameter defines the timeout value for GPT notifications to the Watchdog Manager.
            symbolic name reference WdgMGptChannelRef: destination=GptChannelConfiguration  # Reference to the GPT channel to be used for Watchdog Manager activation.
          container WdgMActivationSchM [0..1]  # Main Function activation.
            float WdgMSupervisionCycle: set at pre-compile  # This parameter defines the schedule period of the main function WdgM_MainFunction_AliveSupervision. Unit: [s]
            float WdgMTriggerCycle: set at pre-compile  # This parameter defines the schedule period of the main function WdgM_MainFunction_Trigger. Unit: [s]
        container WdgMAliveSupervision [0..65535]  # This container collects all configuration parameters of Alive-Supervision.
          boolean WdgMActivationActivated: set at post-build in variant link-time / pre-compile in variant pre-compile  # This parameter shall contain the activation status of the corresponding Supervised Entity.
          integer WdgMAliveSupervisionConfigId: 0..65535, set at post-build in variant link-time / pre-compile in variant pre-compile, symbolic-name-value=true  # This parameter shall contain the identifier of the alive-supervision configuration set.
          integer WdgMExpectedAliveIndications: 1.., set at post-build in variant link-time / pre-compile in variant pre-compile  # This parameter shall contain the amount of expected alive indications within the referenced amount of defined supervision cycles according to corresponding SE.
          integer WdgMFailedSupervisionRefCycleTol: 0.., set at post-build in variant link-time / pre-compile in variant pre-compile  # This parameter shall contain the acceptable amount of failed supervision reference cycles that shall be used by checkup of alive supervision according to corresponding SE.
          integer WdgMMaxMargin: 0.., set at post-build in variant link-time / pre-compile in variant pre-compile  # This parameter shall contain the amount of alive indications that are acceptable to be additional on the expected alive indications within the corresponding supervision reference cycle.
          integer WdgMMinMargin: 0.., set at post-build in variant link-time / pre-compile in variant pre-compile  # This parameter shall contain the amount of alive indications that are acceptable to be missed from the expected alive indications within the corresponding supervision reference cycle.
          integer WdgMSupervisionReferenceCycle: 1.., set at post-build in variant link-time / pre-compile in variant pre-compile  # This parameter shall contain the amount of supervision cycles to be used as reference by the alive-supervision mechanism to perform the checkup with counted alive indications according to corresponding SE.
          symbolic name reference WdgMSupervisedEntityRef: destination=WdgMSupervisedEntity
        container WdgMTrigger [0..255]  # This container collects all configuration parameters for the triggering of hardware watchdogs.
          enumeration WdgMWatchdogMode: {WDGIF_FAST_MODE, WDGIF_OFF_MODE, WDGIF_SLOW_MODE}, set at post-build in variant link-time / pre-compile in variant pre-compile  # This parameter contains the watchdog mode that shall be used for the referenced watchdog in this Watchdog Manager mode. Implementation Type: WdgIf_ModeType
          integer WdgMTriggerReferenceCycle: 1.., set at post-build in variant link-time / pre-compile in variant pre-compile  # This parameter shall contain the amount of trigger cycles to be used as reference by the trigger service of the Watchdog Manager to perform the triggering of the corresponding watchdog.
          symbolic name reference WdgMWatchdogRef: destination=WdgMWatchdog  # This parameter is a reference to the configured watchdog.
    container WdgMGeneral  # Container structures all general configuration parameters of the Watchdog Manager.
      boolean WdgMAliveSupervisionEnabled: set at pre-compile  # Parameter to enable/disable the alive-supervision mechanism. Use Case: no supervised entity assigned true: Alive-supervision mechanism is enabled false: Alive-supervision mechanism is disabled
      boolean WdgMDemAliveSupervisionReport: set at pre-compile  # Parameter to enable/disable alive-supervision error reporting to DEM. true: Alive-supervision error reporting is enabled false: Alive-supervision error reporting is disabled
      boolean WdgMDevErrorDetect: set at pre-compile  # Preprocessor switch to enable/disable development error detection and reporting. Shall be used to remove unneeded code segments regarding DET features true: Development error detection is enabled false: Development error detection is disabled
      boolean WdgMImmediateReset: set at pre-compile  # This parameter enables/disablse the immediate reset feature in case of alive-supervision failure. true: Immediate reset is enabled false: Immediate reset is disabled
      boolean WdgMOffModeEnabled: set at pre-compile  # This parameter enables/disables the selection of the "OffMode" of the watchdog driver. true: "OffMode" selection is allowed false: "OffMode" selection is disallowed
      boolean WdgMVersionInfoApi: set at pre-compile  # Preprocessor switch to enable/disable the existence of the API WdgM_GetVersionInfo. Shall be used to remove unneeded code segments. true: API is enabled false: API is disabled
      integer WdgMNumberOfModes: 1..255, set at pre-compile  # This parameter shall contain the number of configured modes of the Watchdog Manager.
      integer WdgMNumberOfSupervisedEntities: 0..65535, set at pre-compile  # This parameter shall contain the amount of supervised entities configured for the Watchodg Manager.
      integer WdgMNumberOfWatchdogs: 0..255, set at pre-compile  # This parameter shall contain the maximum amount of watchdogs to configured for Watchdog Manager.
      container WdgMSupervisedEntity [0..65535]  # This container collects all common (mode-independent) parameters of a Supervised Entity to be supervised by the Watchdog Manager.
        boolean WdgMDeactivationAccessEnabled: set at pre-compile  # This parameter shall be used to grant the access of the service WdgM_DeactivateAliveSupervision() for affecting the activation status of the corresponding Supervised Entity.
        integer WdgMSupervisedEntityId: 0..65535, set at pre-compile, symbolic-name-value=true  # This parameter shall contain the identifier of he supervised entity.
      container WdgMWatchdog [0..255]  # This container collects all common (mode-independent) parameters of a Watchdog to be triggered by the Watchdog Manager.
        string WdgMWatchdogName: set at pre-compile, symbolic-name-value=true  # This parameter shall contain the symbolic name of the watchdog instance.
        symbolic name reference WdgMDeviceRef: destination=WdgIfDevice  # Reference to one device container of Watchdog Interface. In the referenced container WdgIfDevice, the parameter WdgIfDeviceIndex contains the Index parameter that WdgM has to use for WdgIf_Trigger calls for that watchdog instance.
package /KPIT
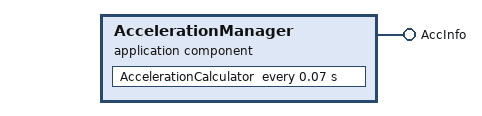
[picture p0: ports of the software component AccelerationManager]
  application software component type AccelerationManager
    provide port AccInfo
  internal behavior AccelerationManagerInternalBhv: component=AccelerationManager
    timing event AccelerationCalculatorTrigger: start-on-event=AccelerationCalculator, period=0.07
    runnable AccelerationCalculator
      data write access AccelerationInfoWriteAccess: data-element=AccInfo
package /Volkswagen/EcuConfiguration
  module config Rte: implementation-config-variant=VARIANT-PRE-COMPILE
    AccelerationManager0 (SwComponentInstance)
      RMappingAMAccCalcul (RunnableEntityMapping): RTEEventRef=AccelerationCalculatorTrigger
